VERSION "374"

NS_ :

BS_:

BU_: SensoricSolutionsOMSRace

BO_ 219 BMS_STATUS: 1 ECU
 SG_ acu_state : 0|8@1+ (1,0) [0|255] "" Vector__XXX

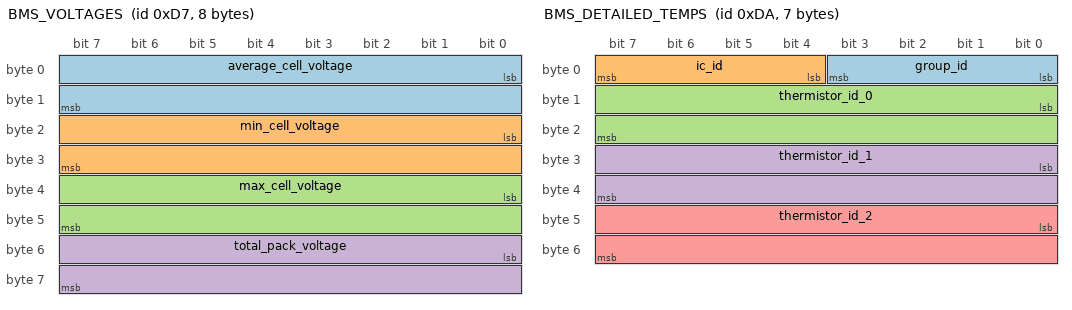
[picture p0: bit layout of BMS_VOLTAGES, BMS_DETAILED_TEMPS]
BO_ 215 BMS_VOLTAGES: 8 ECU
 SG_ average_cell_voltage : 0|16@1+ (0.0001,0) [0.0|6.5535000000000005] "V" Vector__XXX
 SG_ min_cell_voltage : 16|16@1+ (0.0001,0) [0.0|6.5535000000000005] "" Vector__XXX
 SG_ max_cell_voltage : 32|16@1+ (0.0001,0) [0.0|6.5535000000000005] "V" Vector__XXX
 SG_ total_pack_voltage : 48|16@1+ (0.01,0) [0.0|655.35] "" Vector__XXX

BO_ 218 BMS_DETAILED_TEMPS: 7 ECU
 SG_ group_id : 0|4@1+ (1,0) [0|15] "" Vector__XXX
 SG_ ic_id : 4|4@1+ (1,0) [0|15] "" Vector__XXX
 SG_ thermistor_id_0 : 8|16@1- (0.01,0) [-327.68|327.67] "" Vector__XXX
 SG_ thermistor_id_1 : 24|16@1- (0.01,0) [-327.68|327.67] "" Vector__XXX
 SG_ thermistor_id_2 : 40|16@1- (0.01,0) [-327.68|327.67] "" Vector__XXX

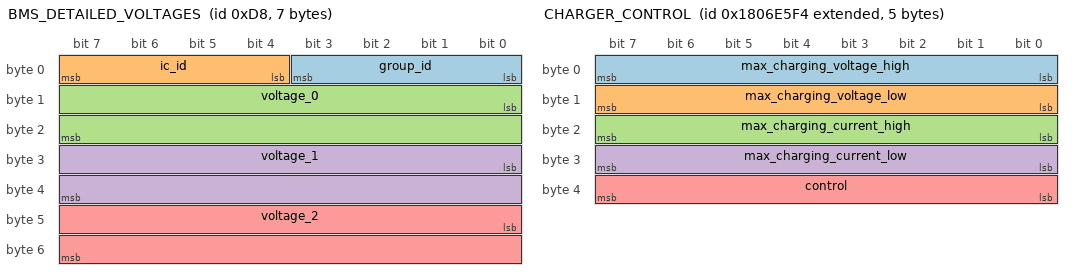
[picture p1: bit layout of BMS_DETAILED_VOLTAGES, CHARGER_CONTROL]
BO_ 216 BMS_DETAILED_VOLTAGES: 7 ECU
 SG_ group_id : 0|4@1+ (1,0) [0|15] "" Vector__XXX
 SG_ ic_id : 4|4@1+ (1,0) [0|15] "" Vector__XXX
 SG_ voltage_0 : 8|16@1+ (0.0001,0) [0.0|6.5535000000000005] "" Vector__XXX
 SG_ voltage_1 : 24|16@1+ (0.0001,0) [0.0|6.5535000000000005] "" Vector__XXX
 SG_ voltage_2 : 40|16@1+ (0.0001,0) [0.0|6.5535000000000005] "" Vector__XXX

BO_ 214 BMS_BOARD_DETAILED_TEMPS: 5 ECU
 SG_ ic_id : 0|4@1+ (1,0) [0|15] "" Vector__XXX
 SG_ temp_0 : 8|16@1- (0.01,0) [-327.68|327.67] "Deg C" Vector__XXX
 SG_ temp_1 : 24|16@1- (0.01,0) [-327.68|327.67] "Deg C" Vector__XXX

BO_ 217 BMS_TEMPS: 6 ECU
 SG_ max_board_temp : 0|16@1- (0.01,0) [-327.68|327.67] "Deg C" Vector__XXX
 SG_ min_cell_temp : 16|16@1- (0.01,0) [-327.68|327.67] "Deg C" Vector__XXX
 SG_ max_cell_temp : 32|16@1- (0.01,0) [-327.68|327.67] "Deg C" Vector__XXX

BO_ 221 CCU_STATUS: 1 ECU
 SG_ charger_enabled : 0|1@1+ (1,0) [0|1] "" Vector__XXX

BO_ 2550588916 CHARGER_CONTROL: 5 ECU
 SG_ max_charging_voltage_high : 0|8@1+ (1,0) [0|255] "" Vector__XXX
 SG_ max_charging_voltage_low : 8|8@1+ (1,0) [0|255] "" Vector__XXX
 SG_ max_charging_current_high : 16|8@1+ (1,0) [0|255] "" Vector__XXX
 SG_ max_charging_current_low : 24|8@1+ (1,0) [0|255] "" Vector__XXX
 SG_ control : 32|8@1+ (1,0) [0|255] "" Vector__XXX

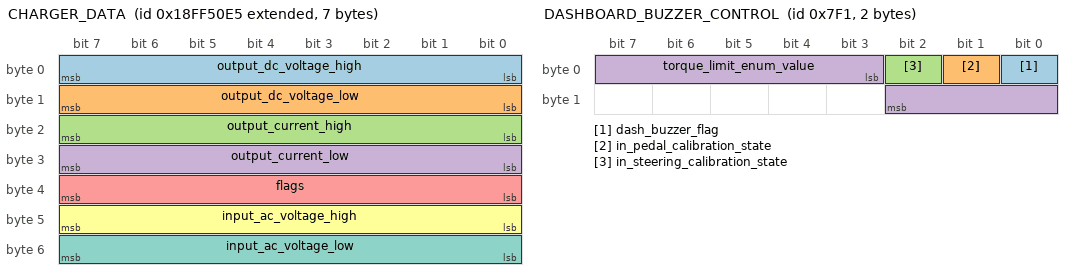
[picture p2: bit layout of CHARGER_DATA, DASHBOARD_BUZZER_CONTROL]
BO_ 2566869221 CHARGER_DATA: 7 ECU
 SG_ output_dc_voltage_high : 0|8@1+ (1,0) [0|255] "" Vector__XXX
 SG_ output_dc_voltage_low : 8|8@1+ (1,0) [0|255] "" Vector__XXX
 SG_ output_current_high : 16|8@1+ (1,0) [0|255] "" Vector__XXX
 SG_ output_current_low : 24|8@1+ (1,0) [0|255] "" Vector__XXX
 SG_ flags : 32|8@1+ (1,0) [0|255] "" Vector__XXX
 SG_ input_ac_voltage_high : 40|8@1+ (1,0) [0|255] "" Vector__XXX
 SG_ input_ac_voltage_low : 48|8@1+ (1,0) [0|255] "" Vector__XXX

BO_ 2033 DASHBOARD_BUZZER_CONTROL: 2 ECU
 SG_ dash_buzzer_flag : 0|1@1+ (1,0) [0|1] "" Vector__XXX
 SG_ in_pedal_calibration_state : 1|1@1+ (1,0) [0|1] "" Vector__XXX
 SG_ in_steering_calibration_state : 2|1@1+ (1,0) [0|1] "" Vector__XXX
 SG_ torque_limit_enum_value : 3|8@1+ (1,0) [0|255] "" Vector__XXX

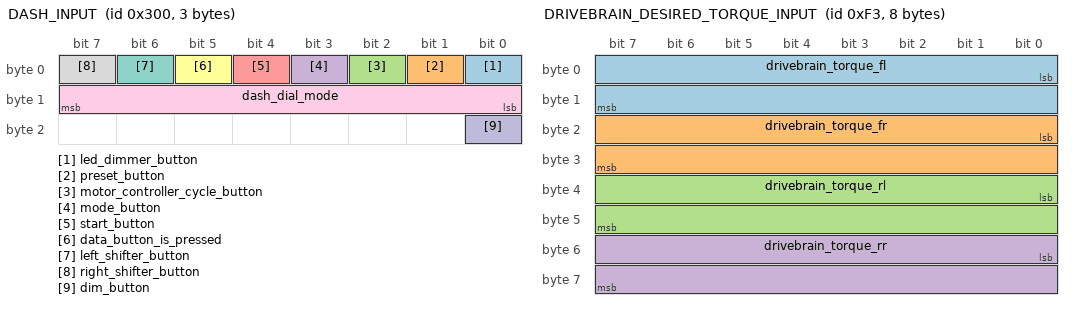
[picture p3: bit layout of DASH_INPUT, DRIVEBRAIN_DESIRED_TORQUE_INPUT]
BO_ 768 DASH_INPUT: 3 ECU
 SG_ led_dimmer_button : 0|1@1+ (1,0) [0|1] "" Vector__XXX
 SG_ preset_button : 1|1@1+ (1,0) [0|1] "" Vector__XXX
 SG_ motor_controller_cycle_button : 2|1@1+ (1,0) [0|1] "" Vector__XXX
 SG_ mode_button : 3|1@1+ (1,0) [0|1] "" Vector__XXX
 SG_ start_button : 4|1@1+ (1,0) [0|1] "" Vector__XXX
 SG_ data_button_is_pressed : 5|1@1+ (1,0) [0|1] "" Vector__XXX
 SG_ left_shifter_button : 6|1@1+ (1,0) [0|1] "" Vector__XXX
 SG_ right_shifter_button : 7|1@1+ (1,0) [0|1] "" Vector__XXX
 SG_ dash_dial_mode : 8|8@1+ (1,0) [0|255] "" Vector__XXX
 SG_ dim_button : 16|1@1+ (1,0) [0|1] "" Vector__XXX

BO_ 243 DRIVEBRAIN_DESIRED_TORQUE_INPUT: 8 ECU
 SG_ drivebrain_torque_fl : 0|16@1- (0.01,0) [-327.68|327.67] "" Vector__XXX
 SG_ drivebrain_torque_fr : 16|16@1- (0.01,0) [-327.68|327.67] "" Vector__XXX
 SG_ drivebrain_torque_rl : 32|16@1- (0.01,0) [-327.68|327.67] "" Vector__XXX
 SG_ drivebrain_torque_rr : 48|16@1- (0.01,0) [-327.68|327.67] "" Vector__XXX

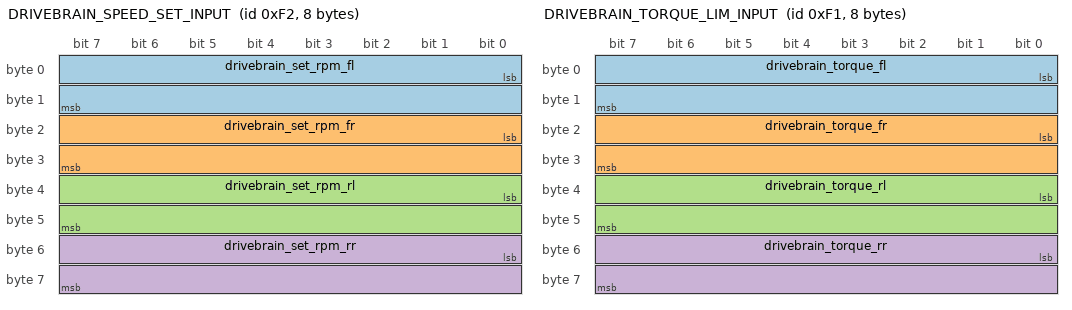
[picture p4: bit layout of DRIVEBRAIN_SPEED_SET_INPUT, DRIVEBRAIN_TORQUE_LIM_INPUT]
BO_ 242 DRIVEBRAIN_SPEED_SET_INPUT: 8 ECU
 SG_ drivebrain_set_rpm_fl : 0|16@1+ (1,0) [0|65535] "" Vector__XXX
 SG_ drivebrain_set_rpm_fr : 16|16@1+ (1,0) [0|65535] "" Vector__XXX
 SG_ drivebrain_set_rpm_rl : 32|16@1+ (1,0) [0|65535] "" Vector__XXX
 SG_ drivebrain_set_rpm_rr : 48|16@1+ (1,0) [0|65535] "" Vector__XXX

BO_ 241 DRIVEBRAIN_TORQUE_LIM_INPUT: 8 ECU
 SG_ drivebrain_torque_fl : 0|16@1- (0.01,0) [-327.68|327.67] "" Vector__XXX
 SG_ drivebrain_torque_fr : 16|16@1- (0.01,0) [-327.68|327.67] "" Vector__XXX
 SG_ drivebrain_torque_rl : 32|16@1- (0.01,0) [-327.68|327.67] "" Vector__XXX
 SG_ drivebrain_torque_rr : 48|16@1- (0.01,0) [-327.68|327.67] "" Vector__XXX

BO_ 244 DRIVEBRAIN_STEERING_INPUT: 2 ECU
 SG_ drivebrain_steering : 0|16@1- (0.01,0) [-327.68|327.67] "degrees" Vector__XXX

BO_ 256 EM_MEASUREMENT: 8 ECU
 SG_ em_current : 7|32@0- (1.52590219e-05,0) [-32768.50001472389|32768.49999946487] "Coulombs" Vector__XXX
 SG_ em_voltage : 39|32@0- (1.52590219e-05,0) [-32768.50001472389|32768.49999946487] "Volts" Vector__XXX

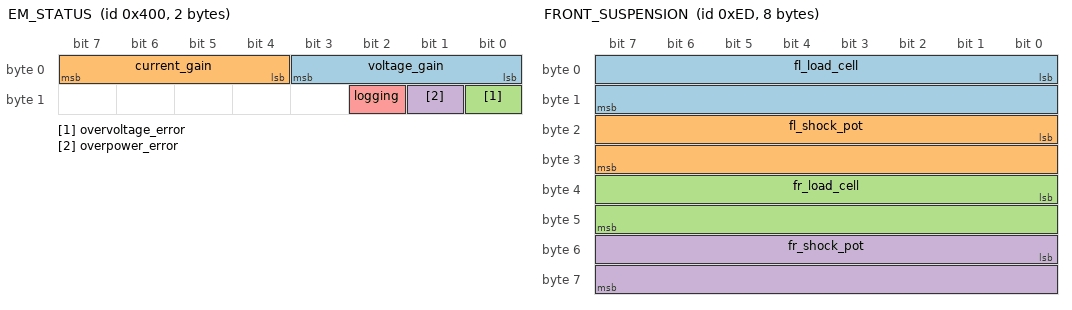
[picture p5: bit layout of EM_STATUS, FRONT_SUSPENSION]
BO_ 1024 EM_STATUS: 2 ECU
 SG_ voltage_gain : 0|4@1+ (1,0) [0|15] "none" Vector__XXX
 SG_ current_gain : 4|4@1+ (1,0) [0|15] "none" Vector__XXX
 SG_ overvoltage_error : 8|1@1+ (1,0) [0|1] "none" Vector__XXX
 SG_ overpower_error : 9|1@1+ (1,0) [0|1] "none" Vector__XXX
 SG_ logging : 10|1@1+ (1,0) [0|1] "none" Vector__XXX

BO_ 237 FRONT_SUSPENSION: 8 ECU
 SG_ fl_load_cell : 0|16@1+ (1,0) [0|65535] "" Vector__XXX
 SG_ fl_shock_pot : 16|16@1+ (0.01,0) [0.0|655.35] "mm" Vector__XXX
 SG_ fr_load_cell : 32|16@1+ (1,0) [0|65535] "" Vector__XXX
 SG_ fr_shock_pot : 48|16@1+ (0.01,0) [0.0|655.35] "" Vector__XXX

BO_ 245 FRONT_THERMISTORS: 8 ECU
 SG_ thermistor_motor_fl : 0|16@1+ (0.005,0) [0.0|327.675] "deg C" Vector__XXX
 SG_ thermistor_motor_fr : 16|16@1+ (0.005,0) [0.0|327.675] "deg C" Vector__XXX

BO_ 153 INV1_CONTROL_INPUT: 6 ECU
 SG_ speed_setpoint_rpm : 0|16@1- (1,0) [-32768|32767] "rpm" Vector__XXX
 SG_ positive_torque_limit : 16|16@1- (0.0097999999999549,0) [-321.1263999985222|321.11659999852225] "Mn" Vector__XXX
 SG_ negative_torque_limit : 32|16@1- (0.0097999999999549,0) [-321.1263999985222|321.11659999852225] "Mn" Vector__XXX

BO_ 261 INV1_CONTROL_PARAMETER: 8 ECU
 SG_ speed_control_kp : 0|16@1+ (1,0) [0|65535] "" Vector__XXX
 SG_ speed_control_ki : 16|16@1+ (1,0) [0|65535] "" Vector__XXX
 SG_ speed_control_kd : 32|16@1+ (1,0) [0|65535] "" Vector__XXX

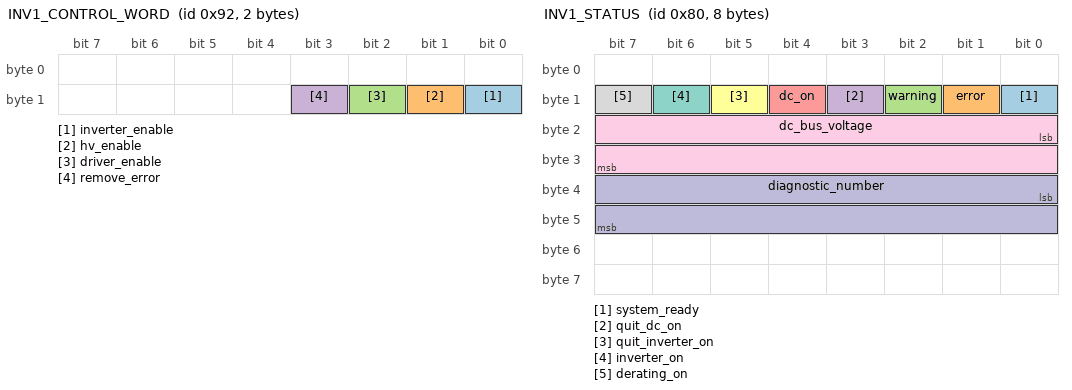
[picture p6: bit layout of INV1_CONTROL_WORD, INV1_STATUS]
BO_ 146 INV1_CONTROL_WORD: 2 ECU
 SG_ inverter_enable : 8|1@1+ (1,0) [0|1] "" Vector__XXX
 SG_ hv_enable : 9|1@1+ (1,0) [0|1] "" Vector__XXX
 SG_ driver_enable : 10|1@1+ (1,0) [0|1] "" Vector__XXX
 SG_ remove_error : 11|1@1+ (1,0) [0|1] "" Vector__XXX

BO_ 130 INV1_DYNAMICS: 8 ECU
 SG_ actual_power_w : 0|32@1+ (1,0) [0|4294967295] "" Vector__XXX
 SG_ actual_torque_nm : 32|16@1- (0.0097999999999549,0) [-321.1263999985222|321.11659999852225] "" Vector__XXX
 SG_ actual_speed_rpm : 48|16@1- (1,0) [-32768|32767] "" Vector__XXX

BO_ 132 INV1_FEEDBACK: 8 ECU
 SG_ speed_control_kp : 0|16@1+ (1,0) [0|65535] "" Vector__XXX
 SG_ speed_control_ki : 16|16@1+ (1,0) [0|65535] "" Vector__XXX
 SG_ speed_control_kd : 32|16@1+ (1,0) [0|65535] "" Vector__XXX

BO_ 131 INV1_POWER: 8 ECU
 SG_ active_power_w : 0|32@1- (1,0) [-2147483648|2147483647] "" Vector__XXX
 SG_ reactive_power_var : 32|32@1- (1,0) [-2147483648|2147483647] "" Vector__XXX

BO_ 128 INV1_STATUS: 8 ECU
 SG_ system_ready : 8|1@1+ (1,0) [0|1] "" Vector__XXX
 SG_ error : 9|1@1+ (1,0) [0|1] "" Vector__XXX
 SG_ warning : 10|1@1+ (1,0) [0|1] "" Vector__XXX
 SG_ quit_dc_on : 11|1@1+ (1,0) [0|1] "" Vector__XXX
 SG_ dc_on : 12|1@1+ (1,0) [0|1] "" Vector__XXX
 SG_ quit_inverter_on : 13|1@1+ (1,0) [0|1] "" Vector__XXX
 SG_ inverter_on : 14|1@1+ (1,0) [0|1] "" Vector__XXX
 SG_ derating_on : 15|1@1+ (1,0) [0|1] "" Vector__XXX
 SG_ dc_bus_voltage : 16|16@1+ (1,0) [0|65535] "V" Vector__XXX
 SG_ diagnostic_number : 32|16@1+ (1,0) [0|65535] "" Vector__XXX

BO_ 129 INV1_TEMPS: 6 ECU
 SG_ motor_temp : 0|16@1- (0.1,0) [-3276.8|3276.7000000000003] "C" Vector__XXX
 SG_ inverter_temp : 16|16@1- (0.1,0) [-3276.8|3276.7000000000003] "C" Vector__XXX
 SG_ igbt_temp : 32|16@1- (0.1,0) [-3276.8|3276.7000000000003] "C" Vector__XXX

BO_ 258 INV2_CONTROL_INPUT: 6 ECU
 SG_ speed_setpoint_rpm : 0|16@1- (1,0) [-32768|32767] "rpm" Vector__XXX
 SG_ positive_torque_limit : 16|16@1- (0.0097999999999549,0) [-321.1263999985222|321.11659999852225] "Mn" Vector__XXX
 SG_ negative_torque_limit : 32|16@1- (0.0097999999999549,0) [-321.1263999985222|321.11659999852225] "Mn" Vector__XXX

BO_ 262 INV2_CONTROL_PARAMETER: 8 ECU
 SG_ speed_control_kp : 0|16@1+ (1,0) [0|65535] "" Vector__XXX
 SG_ speed_control_ki : 16|16@1+ (1,0) [0|65535] "" Vector__XXX
 SG_ speed_control_kd : 32|16@1+ (1,0) [0|65535] "" Vector__XXX

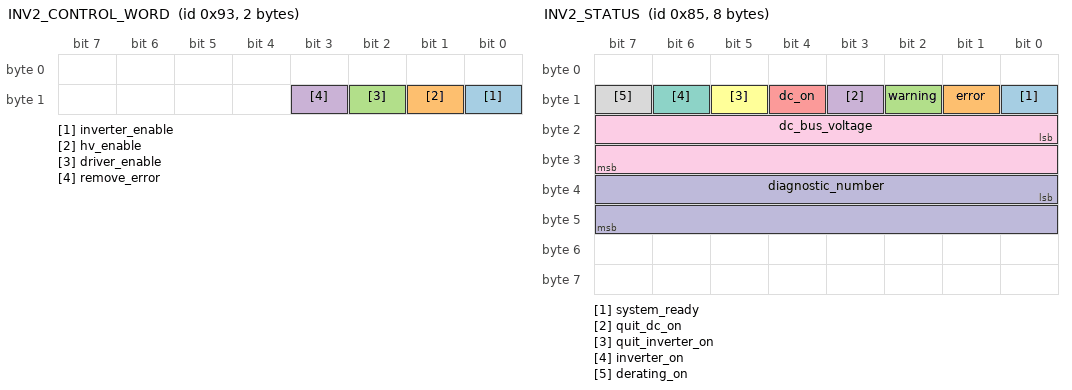
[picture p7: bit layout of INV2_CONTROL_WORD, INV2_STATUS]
BO_ 147 INV2_CONTROL_WORD: 2 ECU
 SG_ inverter_enable : 8|1@1+ (1,0) [0|1] "" Vector__XXX
 SG_ hv_enable : 9|1@1+ (1,0) [0|1] "" Vector__XXX
 SG_ driver_enable : 10|1@1+ (1,0) [0|1] "" Vector__XXX
 SG_ remove_error : 11|1@1+ (1,0) [0|1] "" Vector__XXX

BO_ 135 INV2_DYNAMICS: 8 ECU
 SG_ actual_power_w : 0|32@1+ (1,0) [0|4294967295] "" Vector__XXX
 SG_ actual_torque_nm : 32|16@1- (0.0097999999999549,0) [-321.1263999985222|321.11659999852225] "" Vector__XXX
 SG_ actual_speed_rpm : 48|16@1- (1,0) [-32768|32767] "" Vector__XXX

BO_ 137 INV2_FEEDBACK: 8 ECU
 SG_ speed_control_kp : 0|16@1+ (1,0) [0|65535] "" Vector__XXX
 SG_ speed_control_ki : 16|16@1+ (1,0) [0|65535] "" Vector__XXX
 SG_ speed_control_kd : 32|16@1+ (1,0) [0|65535] "" Vector__XXX

BO_ 136 INV2_POWER: 8 ECU
 SG_ active_power_w : 0|32@1- (1,0) [-2147483648|2147483647] "" Vector__XXX
 SG_ reactive_power_var : 32|32@1- (1,0) [-2147483648|2147483647] "" Vector__XXX

BO_ 133 INV2_STATUS: 8 ECU
 SG_ system_ready : 8|1@1+ (1,0) [0|1] "" Vector__XXX
 SG_ error : 9|1@1+ (1,0) [0|1] "" Vector__XXX
 SG_ warning : 10|1@1+ (1,0) [0|1] "" Vector__XXX
 SG_ quit_dc_on : 11|1@1+ (1,0) [0|1] "" Vector__XXX
 SG_ dc_on : 12|1@1+ (1,0) [0|1] "" Vector__XXX
 SG_ quit_inverter_on : 13|1@1+ (1,0) [0|1] "" Vector__XXX
 SG_ inverter_on : 14|1@1+ (1,0) [0|1] "" Vector__XXX
 SG_ derating_on : 15|1@1+ (1,0) [0|1] "" Vector__XXX
 SG_ dc_bus_voltage : 16|16@1+ (1,0) [0|65535] "V" Vector__XXX
 SG_ diagnostic_number : 32|16@1+ (1,0) [0|65535] "" Vector__XXX

BO_ 134 INV2_TEMPS: 6 ECU
 SG_ motor_temp : 0|16@1- (0.1,0) [-3276.8|3276.7000000000003] "C" Vector__XXX
 SG_ inverter_temp : 16|16@1- (0.1,0) [-3276.8|3276.7000000000003] "C" Vector__XXX
 SG_ igbt_temp : 32|16@1- (0.1,0) [-3276.8|3276.7000000000003] "C" Vector__XXX

BO_ 151 INV3_CONTROL_INPUT: 6 ECU
 SG_ speed_setpoint_rpm : 0|16@1- (1,0) [-32768|32767] "rpm" Vector__XXX
 SG_ positive_torque_limit : 16|16@1- (0.0097999999999549,0) [-321.1263999985222|321.11659999852225] "Mn" Vector__XXX
 SG_ negative_torque_limit : 32|16@1- (0.0097999999999549,0) [-321.1263999985222|321.11659999852225] "Mn" Vector__XXX

BO_ 259 INV3_CONTROL_PARAMETER: 8 ECU
 SG_ speed_control_kp : 0|16@1+ (1,0) [0|65535] "" Vector__XXX
 SG_ speed_control_ki : 16|16@1+ (1,0) [0|65535] "" Vector__XXX
 SG_ speed_control_kd : 32|16@1+ (1,0) [0|65535] "" Vector__XXX

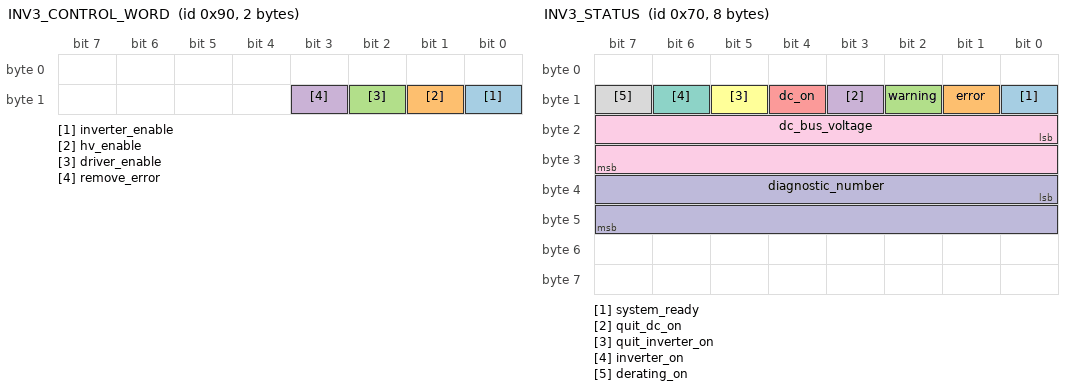
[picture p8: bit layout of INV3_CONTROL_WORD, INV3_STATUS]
BO_ 144 INV3_CONTROL_WORD: 2 ECU
 SG_ inverter_enable : 8|1@1+ (1,0) [0|1] "" Vector__XXX
 SG_ hv_enable : 9|1@1+ (1,0) [0|1] "" Vector__XXX
 SG_ driver_enable : 10|1@1+ (1,0) [0|1] "" Vector__XXX
 SG_ remove_error : 11|1@1+ (1,0) [0|1] "" Vector__XXX

BO_ 114 INV3_DYNAMICS: 8 ECU
 SG_ actual_power_w : 0|32@1+ (1,0) [0|4294967295] "" Vector__XXX
 SG_ actual_torque_nm : 32|16@1- (0.0097999999999549,0) [-321.1263999985222|321.11659999852225] "" Vector__XXX
 SG_ actual_speed_rpm : 48|16@1- (1,0) [-32768|32767] "" Vector__XXX

BO_ 116 INV3_FEEDBACK: 8 ECU
 SG_ speed_control_kp : 0|16@1+ (1,0) [0|65535] "" Vector__XXX
 SG_ speed_control_ki : 16|16@1+ (1,0) [0|65535] "" Vector__XXX
 SG_ speed_control_kd : 32|16@1+ (1,0) [0|65535] "" Vector__XXX

BO_ 115 INV3_POWER: 8 ECU
 SG_ active_power_w : 0|32@1- (1,0) [-2147483648|2147483647] "" Vector__XXX
 SG_ reactive_power_var : 32|32@1- (1,0) [-2147483648|2147483647] "" Vector__XXX

BO_ 112 INV3_STATUS: 8 ECU
 SG_ system_ready : 8|1@1+ (1,0) [0|1] "" Vector__XXX
 SG_ error : 9|1@1+ (1,0) [0|1] "" Vector__XXX
 SG_ warning : 10|1@1+ (1,0) [0|1] "" Vector__XXX
 SG_ quit_dc_on : 11|1@1+ (1,0) [0|1] "" Vector__XXX
 SG_ dc_on : 12|1@1+ (1,0) [0|1] "" Vector__XXX
 SG_ quit_inverter_on : 13|1@1+ (1,0) [0|1] "" Vector__XXX
 SG_ inverter_on : 14|1@1+ (1,0) [0|1] "" Vector__XXX
 SG_ derating_on : 15|1@1+ (1,0) [0|1] "" Vector__XXX
 SG_ dc_bus_voltage : 16|16@1+ (1,0) [0|65535] "V" Vector__XXX
 SG_ diagnostic_number : 32|16@1+ (1,0) [0|65535] "" Vector__XXX

BO_ 113 INV3_TEMPS: 6 ECU
 SG_ motor_temp : 0|16@1- (0.1,0) [-3276.8|3276.7000000000003] "C" Vector__XXX
 SG_ inverter_temp : 16|16@1- (0.1,0) [-3276.8|3276.7000000000003] "C" Vector__XXX
 SG_ igbt_temp : 32|16@1- (0.1,0) [-3276.8|3276.7000000000003] "C" Vector__XXX

BO_ 152 INV4_CONTROL_INPUT: 6 ECU
 SG_ speed_setpoint_rpm : 0|16@1- (1,0) [-32768|32767] "rpm" Vector__XXX
 SG_ positive_torque_limit : 16|16@1- (0.0097999999999549,0) [-321.1263999985222|321.11659999852225] "Mn" Vector__XXX
 SG_ negative_torque_limit : 32|16@1- (0.0097999999999549,0) [-321.1263999985222|321.11659999852225] "Mn" Vector__XXX

BO_ 260 INV4_CONTROL_PARAMETER: 8 ECU
 SG_ speed_control_kp : 0|16@1+ (1,0) [0|65535] "" Vector__XXX
 SG_ speed_control_ki : 16|16@1+ (1,0) [0|65535] "" Vector__XXX
 SG_ speed_control_kd : 32|16@1+ (1,0) [0|65535] "" Vector__XXX

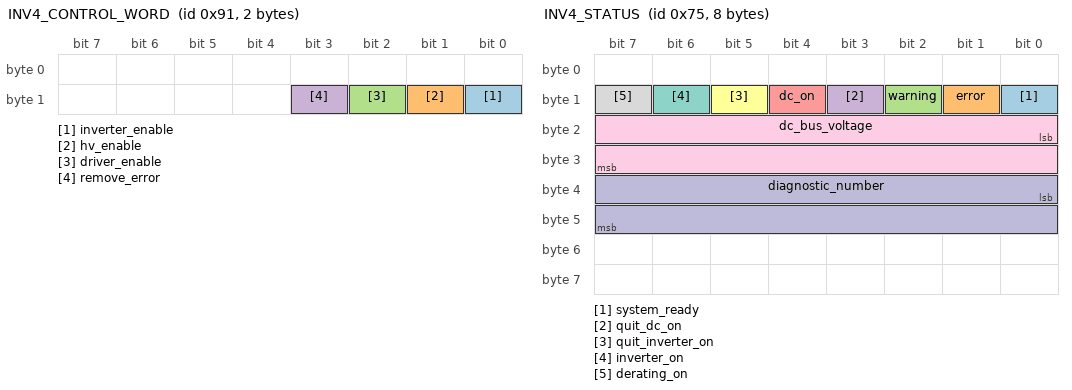
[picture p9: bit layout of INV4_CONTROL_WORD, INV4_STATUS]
BO_ 145 INV4_CONTROL_WORD: 2 ECU
 SG_ inverter_enable : 8|1@1+ (1,0) [0|1] "" Vector__XXX
 SG_ hv_enable : 9|1@1+ (1,0) [0|1] "" Vector__XXX
 SG_ driver_enable : 10|1@1+ (1,0) [0|1] "" Vector__XXX
 SG_ remove_error : 11|1@1+ (1,0) [0|1] "" Vector__XXX

BO_ 119 INV4_DYNAMICS: 8 ECU
 SG_ actual_power_w : 0|32@1+ (1,0) [0|4294967295] "" Vector__XXX
 SG_ actual_torque_nm : 32|16@1- (0.0097999999999549,0) [-321.1263999985222|321.11659999852225] "" Vector__XXX
 SG_ actual_speed_rpm : 48|16@1- (1,0) [-32768|32767] "" Vector__XXX

BO_ 121 INV4_FEEDBACK: 8 ECU
 SG_ speed_control_kp : 0|16@1+ (1,0) [0|65535] "" Vector__XXX
 SG_ speed_control_ki : 16|16@1+ (1,0) [0|65535] "" Vector__XXX
 SG_ speed_control_kd : 32|16@1+ (1,0) [0|65535] "" Vector__XXX

BO_ 120 INV4_POWER: 8 ECU
 SG_ active_power_w : 0|32@1- (1,0) [-2147483648|2147483647] "" Vector__XXX
 SG_ reactive_power_var : 32|32@1- (1,0) [-2147483648|2147483647] "" Vector__XXX

BO_ 117 INV4_STATUS: 8 ECU
 SG_ system_ready : 8|1@1+ (1,0) [0|1] "" Vector__XXX
 SG_ error : 9|1@1+ (1,0) [0|1] "" Vector__XXX
 SG_ warning : 10|1@1+ (1,0) [0|1] "" Vector__XXX
 SG_ quit_dc_on : 11|1@1+ (1,0) [0|1] "" Vector__XXX
 SG_ dc_on : 12|1@1+ (1,0) [0|1] "" Vector__XXX
 SG_ quit_inverter_on : 13|1@1+ (1,0) [0|1] "" Vector__XXX
 SG_ inverter_on : 14|1@1+ (1,0) [0|1] "" Vector__XXX
 SG_ derating_on : 15|1@1+ (1,0) [0|1] "" Vector__XXX
 SG_ dc_bus_voltage : 16|16@1+ (1,0) [0|65535] "V" Vector__XXX
 SG_ diagnostic_number : 32|16@1+ (1,0) [0|65535] "" Vector__XXX

BO_ 118 INV4_TEMPS: 6 ECU
 SG_ motor_temp : 0|16@1- (0.1,0) [-3276.8|3276.7000000000003] "C" Vector__XXX
 SG_ inverter_temp : 16|16@1- (0.1,0) [-3276.8|3276.7000000000003] "C" Vector__XXX
 SG_ igbt_temp : 32|16@1- (0.1,0) [-3276.8|3276.7000000000003] "C" Vector__XXX

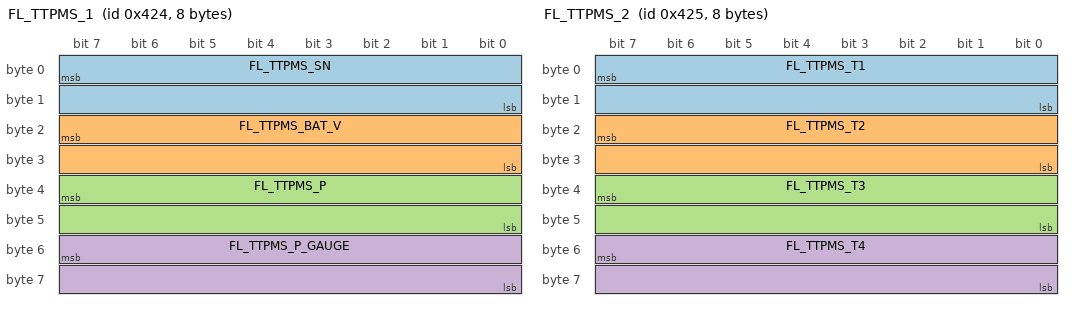
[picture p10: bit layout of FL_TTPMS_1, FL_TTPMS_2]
BO_ 1060 FL_TTPMS_1: 8 ECU
 SG_ FL_TTPMS_SN : 7|16@0+ (1,0) [0|65535] "" Vector__XXX
 SG_ FL_TTPMS_BAT_V : 23|16@0+ (1,0) [0|65535] "mV" Vector__XXX
 SG_ FL_TTPMS_P : 39|16@0- (0.1,3000) [-276.8000000000002|6276.700000000001] "mbar" Vector__XXX
 SG_ FL_TTPMS_P_GAUGE : 55|16@0+ (1,0) [0|65535] "mbar" Vector__XXX

BO_ 1061 FL_TTPMS_2: 8 ECU
 SG_ FL_TTPMS_T1 : 7|16@0+ (0.1,-100) [-100.0|6453.5] "°C" Vector__XXX
 SG_ FL_TTPMS_T2 : 23|16@0+ (0.1,-100) [-100.0|6453.5] "°C" Vector__XXX
 SG_ FL_TTPMS_T3 : 39|16@0+ (0.1,-100) [-100.0|6453.5] "°C" Vector__XXX
 SG_ FL_TTPMS_T4 : 55|16@0+ (0.1,-100) [-100.0|6453.5] "°C" Vector__XXX

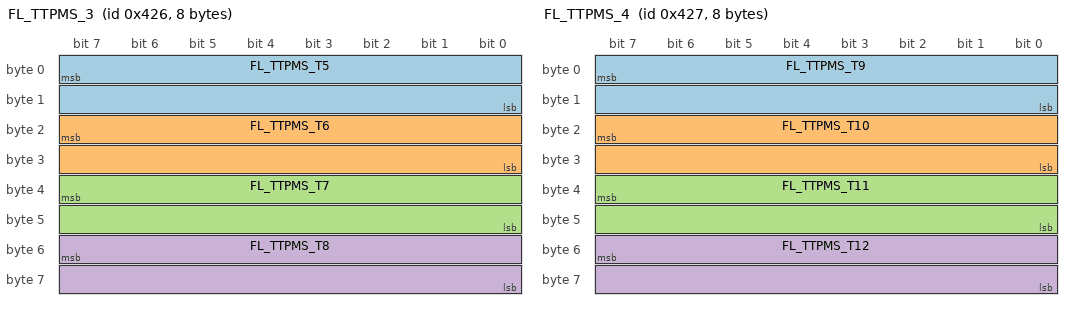
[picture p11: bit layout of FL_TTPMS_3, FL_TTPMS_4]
BO_ 1062 FL_TTPMS_3: 8 ECU
 SG_ FL_TTPMS_T5 : 7|16@0+ (0.1,-100) [-100.0|6453.5] "°C" Vector__XXX
 SG_ FL_TTPMS_T6 : 23|16@0+ (0.1,-100) [-100.0|6453.5] "°C" Vector__XXX
 SG_ FL_TTPMS_T7 : 39|16@0+ (0.1,-100) [-100.0|6453.5] "°C" Vector__XXX
 SG_ FL_TTPMS_T8 : 55|16@0+ (0.1,-100) [-100.0|6453.5] "°C" Vector__XXX

BO_ 1063 FL_TTPMS_4: 8 ECU
 SG_ FL_TTPMS_T9 : 7|16@0+ (0.1,-100) [-100.0|6453.5] "°C" Vector__XXX
 SG_ FL_TTPMS_T10 : 23|16@0+ (0.1,-100) [-100.0|6453.5] "°C" Vector__XXX
 SG_ FL_TTPMS_T11 : 39|16@0+ (0.1,-100) [-100.0|6453.5] "°C" Vector__XXX
 SG_ FL_TTPMS_T12 : 55|16@0+ (0.1,-100) [-100.0|6453.5] "°C" Vector__XXX

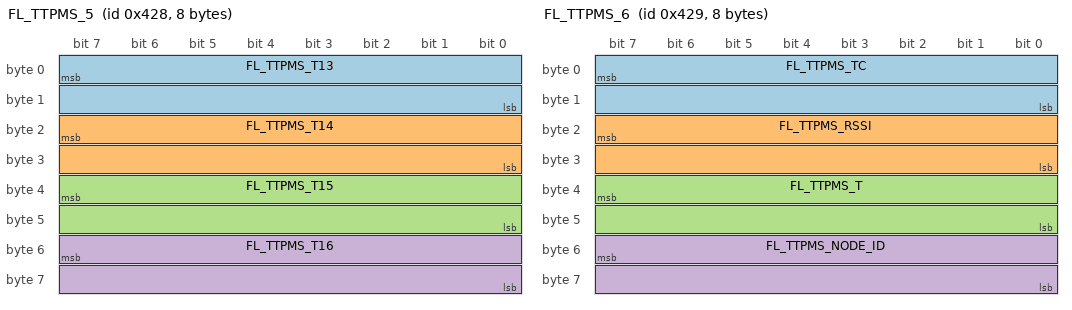
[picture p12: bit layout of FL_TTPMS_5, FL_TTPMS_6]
BO_ 1064 FL_TTPMS_5: 8 ECU
 SG_ FL_TTPMS_T13 : 7|16@0+ (0.1,-100) [-100.0|6453.5] "°C" Vector__XXX
 SG_ FL_TTPMS_T14 : 23|16@0+ (0.1,-100) [-100.0|6453.5] "°C" Vector__XXX
 SG_ FL_TTPMS_T15 : 39|16@0+ (0.1,-100) [-100.0|6453.5] "°C" Vector__XXX
 SG_ FL_TTPMS_T16 : 55|16@0+ (0.1,-100) [-100.0|6453.5] "°C" Vector__XXX

BO_ 1065 FL_TTPMS_6: 8 ECU
 SG_ FL_TTPMS_TC : 7|16@0+ (1,0) [0|65535] "" Vector__XXX
 SG_ FL_TTPMS_RSSI : 23|16@0- (1,0) [-32768|32767] "dBm" Vector__XXX
 SG_ FL_TTPMS_T : 39|16@0+ (0.1,-100) [-100.0|6453.5] "°C" Vector__XXX
 SG_ FL_TTPMS_NODE_ID : 55|16@0+ (1,0) [0|65535] "" Vector__XXX

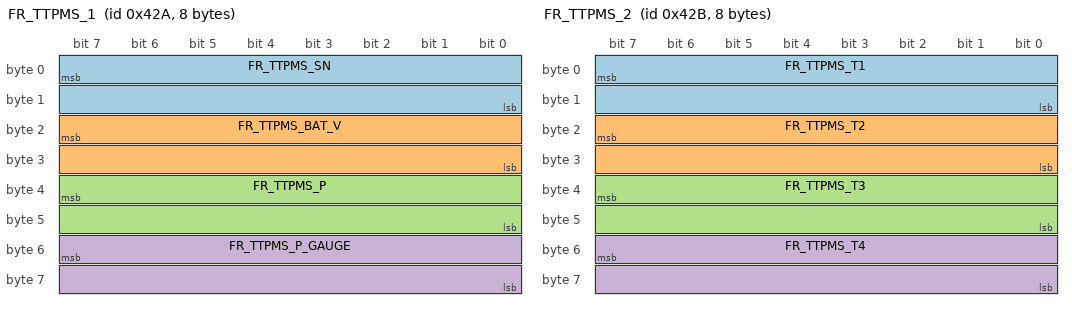
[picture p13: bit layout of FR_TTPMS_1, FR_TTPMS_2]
BO_ 1066 FR_TTPMS_1: 8 ECU
 SG_ FR_TTPMS_SN : 7|16@0+ (1,0) [0|65535] "" Vector__XXX
 SG_ FR_TTPMS_BAT_V : 23|16@0+ (1,0) [0|65535] "mV" Vector__XXX
 SG_ FR_TTPMS_P : 39|16@0- (0.1,3000) [-276.8000000000002|6276.700000000001] "mbar" Vector__XXX
 SG_ FR_TTPMS_P_GAUGE : 55|16@0+ (1,0) [0|65535] "mbar" Vector__XXX

BO_ 1067 FR_TTPMS_2: 8 ECU
 SG_ FR_TTPMS_T1 : 7|16@0+ (0.1,-100) [-100.0|6453.5] "°C" Vector__XXX
 SG_ FR_TTPMS_T2 : 23|16@0+ (0.1,-100) [-100.0|6453.5] "°C" Vector__XXX
 SG_ FR_TTPMS_T3 : 39|16@0+ (0.1,-100) [-100.0|6453.5] "°C" Vector__XXX
 SG_ FR_TTPMS_T4 : 55|16@0+ (0.1,-100) [-100.0|6453.5] "°C" Vector__XXX

BO_ 1068 FR_TTPMS_3: 8 ECU
 SG_ FR_TTPMS_T5 : 7|16@0+ (0.1,-100) [-100.0|6453.5] "°C" Vector__XXX
 SG_ FR_TTPMS_T6 : 23|16@0+ (0.1,-100) [-100.0|6453.5] "°C" Vector__XXX
 SG_ FR_TTPMS_T7 : 39|16@0+ (0.1,-100) [-100.0|6453.5] "°C" Vector__XXX
 SG_ FR_TTPMS_T8 : 55|16@0+ (0.1,-100) [-100.0|6453.5] "°C" Vector__XXX

BO_ 1069 FR_TTPMS_4: 8 ECU
 SG_ FR_TTPMS_T9 : 7|16@0+ (0.1,-100) [-100.0|6453.5] "°C" Vector__XXX
 SG_ FR_TTPMS_T10 : 23|16@0+ (0.1,-100) [-100.0|6453.5] "°C" Vector__XXX
 SG_ FR_TTPMS_T11 : 39|16@0+ (0.1,-100) [-100.0|6453.5] "°C" Vector__XXX
 SG_ FR_TTPMS_T12 : 55|16@0+ (0.1,-100) [-100.0|6453.5] "°C" Vector__XXX

BO_ 1070 FR_TTPMS_5: 8 ECU
 SG_ FR_TTPMS_T13 : 7|16@0+ (0.1,-100) [-100.0|6453.5] "°C" Vector__XXX
 SG_ FR_TTPMS_T14 : 23|16@0+ (0.1,-100) [-100.0|6453.5] "°C" Vector__XXX
 SG_ FR_TTPMS_T15 : 39|16@0+ (0.1,-100) [-100.0|6453.5] "°C" Vector__XXX
 SG_ FR_TTPMS_T16 : 55|16@0+ (0.1,-100) [-100.0|6453.5] "°C" Vector__XXX

BO_ 1071 FR_TTPMS_6: 8 ECU
 SG_ FR_TTPMS_TC : 7|16@0+ (1,0) [0|65535] "" Vector__XXX
 SG_ FR_TTPMS_RSSI : 23|16@0- (1,0) [-32768|32767] "dBm" Vector__XXX
 SG_ FR_TTPMS_T : 39|16@0+ (0.1,-100) [-100.0|6453.5] "°C" Vector__XXX
 SG_ FR_TTPMS_NODE_ID : 55|16@0+ (1,0) [0|65535] "" Vector__XXX

BO_ 1072 RL_TTPMS_1: 8 ECU
 SG_ RL_TTPMS_SN : 7|16@0+ (1,0) [0|65535] "" Vector__XXX
 SG_ RL_TTPMS_BAT_V : 23|16@0+ (1,0) [0|65535] "mV" Vector__XXX
 SG_ RL_TTPMS_P : 39|16@0- (0.1,3000) [-276.8000000000002|6276.700000000001] "mbar" Vector__XXX
 SG_ RL_TTPMS_P_GAUGE : 55|16@0+ (1,0) [0|65535] "mbar" Vector__XXX

BO_ 1073 RL_TTPMS_2: 8 ECU
 SG_ RL_TTPMS_T1 : 7|16@0+ (0.1,-100) [-100.0|6453.5] "°C" Vector__XXX
 SG_ RL_TTPMS_T2 : 23|16@0+ (0.1,-100) [-100.0|6453.5] "°C" Vector__XXX
 SG_ RL_TTPMS_T3 : 39|16@0+ (0.1,-100) [-100.0|6453.5] "°C" Vector__XXX
 SG_ RL_TTPMS_T4 : 55|16@0+ (0.1,-100) [-100.0|6453.5] "°C" Vector__XXX

BO_ 1074 RL_TTPMS_3: 8 ECU
 SG_ RL_TTPMS_T5 : 7|16@0+ (0.1,-100) [-100.0|6453.5] "°C" Vector__XXX
 SG_ RL_TTPMS_T6 : 23|16@0+ (0.1,-100) [-100.0|6453.5] "°C" Vector__XXX
 SG_ RL_TTPMS_T7 : 39|16@0+ (0.1,-100) [-100.0|6453.5] "°C" Vector__XXX
 SG_ RL_TTPMS_T8 : 55|16@0+ (0.1,-100) [-100.0|6453.5] "°C" Vector__XXX

BO_ 1075 RL_TTPMS_4: 8 ECU
 SG_ RL_TTPMS_T9 : 7|16@0+ (0.1,-100) [-100.0|6453.5] "°C" Vector__XXX
 SG_ RL_TTPMS_T10 : 23|16@0+ (0.1,-100) [-100.0|6453.5] "°C" Vector__XXX
 SG_ RL_TTPMS_T11 : 39|16@0+ (0.1,-100) [-100.0|6453.5] "°C" Vector__XXX
 SG_ RL_TTPMS_T12 : 55|16@0+ (0.1,-100) [-100.0|6453.5] "°C" Vector__XXX

BO_ 1076 RL_TTPMS_5: 8 ECU
 SG_ RL_TTPMS_T13 : 7|16@0+ (0.1,-100) [-100.0|6453.5] "°C" Vector__XXX
 SG_ RL_TTPMS_T14 : 23|16@0+ (0.1,-100) [-100.0|6453.5] "°C" Vector__XXX
 SG_ RL_TTPMS_T15 : 39|16@0+ (0.1,-100) [-100.0|6453.5] "°C" Vector__XXX
 SG_ RL_TTPMS_T16 : 55|16@0+ (0.1,-100) [-100.0|6453.5] "°C" Vector__XXX

BO_ 1077 RL_TTPMS_6: 8 ECU
 SG_ RL_TTPMS_TC : 7|16@0+ (1,0) [0|65535] "" Vector__XXX
 SG_ RL_TTPMS_RSSI : 23|16@0- (1,0) [-32768|32767] "dBm" Vector__XXX
 SG_ RL_TTPMS_T : 39|16@0+ (0.1,-100) [-100.0|6453.5] "°C" Vector__XXX
 SG_ RL_TTPMS_NODE_ID : 55|16@0+ (1,0) [0|65535] "" Vector__XXX

BO_ 1078 RR_TTPMS_1: 8 ECU
 SG_ RR_TTPMS_SN : 7|16@0+ (1,0) [0|65535] "" Vector__XXX
 SG_ RR_TTPMS_BAT_V : 23|16@0+ (1,0) [0|65535] "mV" Vector__XXX
 SG_ RR_TTPMS_P : 39|16@0- (0.1,3000) [-276.8000000000002|6276.700000000001] "mbar" Vector__XXX
 SG_ RR_TTPMS_P_GAUGE : 55|16@0+ (1,0) [0|65535] "mbar" Vector__XXX

BO_ 1079 RR_TTPMS_2: 8 ECU
 SG_ RR_TTPMS_T1 : 7|16@0+ (0.1,-100) [-100.0|6453.5] "°C" Vector__XXX
 SG_ RR_TTPMS_T2 : 23|16@0+ (0.1,-100) [-100.0|6453.5] "°C" Vector__XXX
 SG_ RR_TTPMS_T3 : 39|16@0+ (0.1,-100) [-100.0|6453.5] "°C" Vector__XXX
 SG_ RR_TTPMS_T4 : 55|16@0+ (0.1,-100) [-100.0|6453.5] "°C" Vector__XXX

BO_ 1080 RR_TTPMS_3: 8 ECU
 SG_ RR_TTPMS_T5 : 7|16@0+ (0.1,-100) [-100.0|6453.5] "°C" Vector__XXX
 SG_ RR_TTPMS_T6 : 23|16@0+ (0.1,-100) [-100.0|6453.5] "°C" Vector__XXX
 SG_ RR_TTPMS_T7 : 39|16@0+ (0.1,-100) [-100.0|6453.5] "°C" Vector__XXX
 SG_ RR_TTPMS_T8 : 55|16@0+ (0.1,-100) [-100.0|6453.5] "°C" Vector__XXX

BO_ 1081 RR_TTPMS_4: 8 ECU
 SG_ RR_TTPMS_T9 : 7|16@0+ (0.1,-100) [-100.0|6453.5] "°C" Vector__XXX
 SG_ RR_TTPMS_T10 : 23|16@0+ (0.1,-100) [-100.0|6453.5] "°C" Vector__XXX
 SG_ RR_TTPMS_T11 : 39|16@0+ (0.1,-100) [-100.0|6453.5] "°C" Vector__XXX
 SG_ RR_TTPMS_T12 : 55|16@0+ (0.1,-100) [-100.0|6453.5] "°C" Vector__XXX

BO_ 1082 RR_TTPMS_5: 8 ECU
 SG_ RR_TTPMS_T13 : 7|16@0+ (0.1,-100) [-100.0|6453.5] "°C" Vector__XXX
 SG_ RR_TTPMS_T14 : 23|16@0+ (0.1,-100) [-100.0|6453.5] "°C" Vector__XXX
 SG_ RR_TTPMS_T15 : 39|16@0+ (0.1,-100) [-100.0|6453.5] "°C" Vector__XXX
 SG_ RR_TTPMS_T16 : 55|16@0+ (0.1,-100) [-100.0|6453.5] "°C" Vector__XXX

BO_ 1083 RR_TTPMS_6: 8 ECU
 SG_ RR_TTPMS_TC : 7|16@0+ (1,0) [0|65535] "" Vector__XXX
 SG_ RR_TTPMS_RSSI : 23|16@0- (1,0) [-32768|32767] "dBm" Vector__XXX
 SG_ RR_TTPMS_T : 39|16@0+ (0.1,-100) [-100.0|6453.5] "°C" Vector__XXX
 SG_ RR_TTPMS_NODE_ID : 55|16@0+ (1,0) [0|65535] "" Vector__XXX

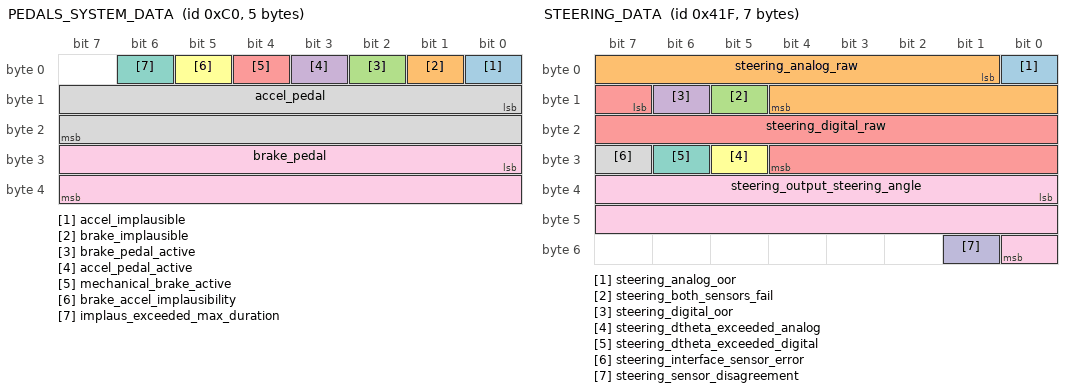
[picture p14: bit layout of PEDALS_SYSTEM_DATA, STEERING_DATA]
BO_ 192 PEDALS_SYSTEM_DATA: 5 ECU
 SG_ accel_implausible : 0|1@1+ (1,0) [0|1] "" Vector__XXX
 SG_ brake_implausible : 1|1@1+ (1,0) [0|1] "" Vector__XXX
 SG_ brake_pedal_active : 2|1@1+ (1,0) [0|1] "" Vector__XXX
 SG_ accel_pedal_active : 3|1@1+ (1,0) [0|1] "" Vector__XXX
 SG_ mechanical_brake_active : 4|1@1+ (1,0) [0|1] "" Vector__XXX
 SG_ brake_accel_implausibility : 5|1@1+ (1,0) [0|1] "" Vector__XXX
 SG_ implaus_exceeded_max_duration : 6|1@1+ (1,0) [0|1] "" Vector__XXX
 SG_ accel_pedal : 8|16@1+ (1.5259e-05,0) [0.0|0.9999985650000001] "" Vector__XXX
 SG_ brake_pedal : 24|16@1+ (1.5259e-05,0) [0.0|0.9999985650000001] "" Vector__XXX

BO_ 228 REAR_SUSPENSION: 8 ECU
 SG_ rl_load_cell : 0|16@1+ (1,0) [0|65535] "" Vector__XXX
 SG_ rr_load_cell : 16|16@1+ (1,0) [0|65535] "" Vector__XXX
 SG_ rl_shock_pot : 32|16@1+ (0.01,0) [0.0|655.35] "" Vector__XXX
 SG_ rr_shock_pot : 48|16@1+ (0.01,0) [0.0|655.35] "" Vector__XXX

BO_ 238 REAR_THERMISTORS_DATA: 8 ECU
 SG_ thermistor_0_deg_C : 0|16@1+ (0.005,0) [0.0|327.675] "deg C" Vector__XXX
 SG_ thermistor_1_deg_C : 16|16@1+ (0.005,0) [0.0|327.675] "deg C" Vector__XXX
 SG_ thermistor_2_deg_C : 32|16@1+ (0.005,0) [0.0|327.675] "deg C" Vector__XXX
 SG_ thermistor_3_deg_C : 48|16@1+ (0.005,0) [0.0|327.675] "deg C" Vector__XXX

BO_ 1054 STATE_OF_CHARGE: 8 ECU
 SG_ SoC : 0|16@1+ (0.01,0) [0.0|655.35] "percent" Vector__XXX
 SG_ min_cell_voltage_est : 16|16@1+ (0.0001,0) [0.0|6.5535000000000005] "volts" Vector__XXX
 SG_ charge_coulombs : 32|32@1+ (0.0001,0) [0.0|429496.7295] "Coulombs" Vector__XXX

BO_ 1055 STEERING_DATA: 7 ECU
 SG_ steering_analog_oor : 0|1@1+ (1,0) [0|1] "" Vector__XXX
 SG_ steering_analog_raw : 1|12@1+ (1,0) [0|4095] "" Vector__XXX
 SG_ steering_both_sensors_fail : 13|1@1+ (1,0) [0|1] "" Vector__XXX
 SG_ steering_digital_oor : 14|1@1+ (1,0) [0|1] "" Vector__XXX
 SG_ steering_digital_raw : 15|14@1+ (1,0) [0|16383] "" Vector__XXX
 SG_ steering_dtheta_exceeded_analog : 29|1@1+ (1,0) [0|1] "" Vector__XXX
 SG_ steering_dtheta_exceeded_digital : 30|1@1+ (1,0) [0|1] "" Vector__XXX
 SG_ steering_interface_sensor_error : 31|1@1+ (1,0) [0|1] "" Vector__XXX
 SG_ steering_output_steering_angle : 32|17@1+ (0.01,-360) [-360.0|950.71] "degrees" Vector__XXX
 SG_ steering_sensor_disagreement : 49|1@1+ (1,0) [0|1] "" Vector__XXX

BO_ 2047 VEHM_ALPHA: 8 ECU
 SG_ vehm_alpha_deg_fl : 0|16@1- (0.001,0) [-32.768|32.767] "deg" Vector__XXX
 SG_ vehm_alpha_deg_fr : 16|16@1- (0.001,0) [-32.768|32.767] "deg" Vector__XXX
 SG_ vehm_alpha_deg_rl : 32|16@1- (0.001,0) [-32.768|32.767] "deg" Vector__XXX
 SG_ vehm_alpha_deg_rr : 48|16@1- (0.001,0) [-32.768|32.767] "deg" Vector__XXX

BO_ 2031 VEHM_BETA: 8 ECU
 SG_ vehm_beta_deg : 0|16@1- (0.001,0) [-32.768|32.767] "deg" Vector__XXX

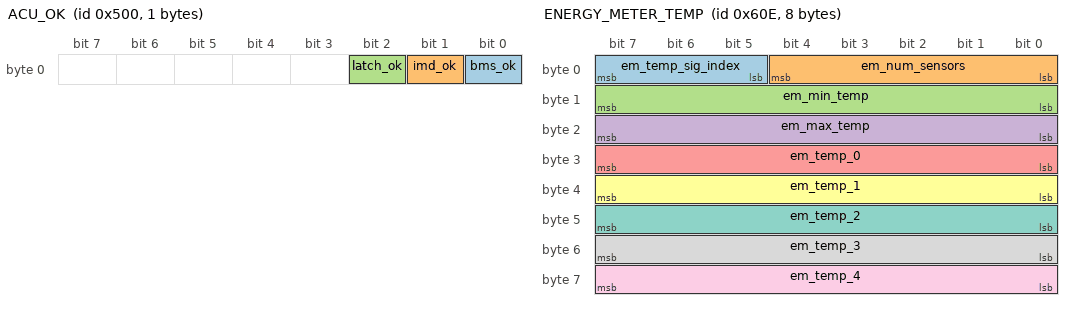
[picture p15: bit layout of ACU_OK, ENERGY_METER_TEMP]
BO_ 1280 ACU_OK: 1 ECU
 SG_ bms_ok : 0|1@1+ (1,0) [0|1] "" Vector__XXX
 SG_ imd_ok : 1|1@1+ (1,0) [0|1] "" Vector__XXX
 SG_ latch_ok : 2|1@1+ (1,0) [0|1] "" Vector__XXX

BO_ 519 CAR_STATES: 3 ECU
 SG_ vehicle_state : 0|8@1+ (1,0) [0|255] "" Vector__XXX
 SG_ drivetrain_state : 8|8@1+ (1,0) [0|255] "" Vector__XXX
 SG_ drivebrain_in_control : 16|1@1+ (1,0) [0|1] "" Vector__XXX

BO_ 1220 FL_IR_TEMP_CH1_CH4: 8 ECU
 SG_ ir_temp_channel_1 : 7|16@0+ (0.1,-100) [-100.0|6453.5] "deg C" Vector__XXX
 SG_ ir_temp_channel_2 : 23|16@0+ (0.1,-100) [-100.0|6453.5] "deg C" Vector__XXX
 SG_ ir_temp_channel_3 : 39|16@0+ (0.1,-100) [-100.0|6453.5] "deg C" Vector__XXX
 SG_ ir_temp_channel_4 : 55|16@0+ (0.1,-100) [-100.0|6453.5] "deg C" Vector__XXX

BO_ 1221 FL_IR_TEMP_CH5_CH8: 8 ECU
 SG_ ir_temp_channel_5 : 7|16@0+ (0.1,-100) [-100.0|6453.5] "deg C" Vector__XXX
 SG_ ir_temp_channel_6 : 23|16@0+ (0.1,-100) [-100.0|6453.5] "deg C" Vector__XXX
 SG_ ir_temp_channel_7 : 39|16@0+ (0.1,-100) [-100.0|6453.5] "deg C" Vector__XXX
 SG_ ir_temp_channel_8 : 55|16@0+ (0.1,-100) [-100.0|6453.5] "deg C" Vector__XXX

BO_ 1222 FL_IR_TEMP_CH9_CH12: 8 ECU
 SG_ ir_temp_channel_9 : 7|16@0+ (0.1,-100) [-100.0|6453.5] "deg C" Vector__XXX
 SG_ ir_temp_channel_10 : 23|16@0+ (0.1,-100) [-100.0|6453.5] "deg C" Vector__XXX
 SG_ ir_temp_channel_11 : 39|16@0+ (0.1,-100) [-100.0|6453.5] "deg C" Vector__XXX
 SG_ ir_temp_channel_12 : 55|16@0+ (0.1,-100) [-100.0|6453.5] "deg C" Vector__XXX

BO_ 1223 FL_IR_TEMP_CH13_CH16: 8 ECU
 SG_ ir_temp_channel_13 : 7|16@0+ (0.1,-100) [-100.0|6453.5] "deg C" Vector__XXX
 SG_ ir_temp_channel_14 : 23|16@0+ (0.1,-100) [-100.0|6453.5] "deg C" Vector__XXX
 SG_ ir_temp_channel_15 : 39|16@0+ (0.1,-100) [-100.0|6453.5] "deg C" Vector__XXX
 SG_ ir_temp_channel_16 : 55|16@0+ (0.1,-100) [-100.0|6453.5] "deg C" Vector__XXX

BO_ 1224 FR_IR_TEMP_CH1_CH4: 8 ECU
 SG_ ir_temp_channel_1 : 7|16@0+ (0.1,-100) [-100.0|6453.5] "deg C" Vector__XXX
 SG_ ir_temp_channel_2 : 23|16@0+ (0.1,-100) [-100.0|6453.5] "deg C" Vector__XXX
 SG_ ir_temp_channel_3 : 39|16@0+ (0.1,-100) [-100.0|6453.5] "deg C" Vector__XXX
 SG_ ir_temp_channel_4 : 55|16@0+ (0.1,-100) [-100.0|6453.5] "deg C" Vector__XXX

BO_ 1225 FR_IR_TEMP_CH5_CH8: 8 ECU
 SG_ ir_temp_channel_5 : 7|16@0+ (0.1,-100) [-100.0|6453.5] "deg C" Vector__XXX
 SG_ ir_temp_channel_6 : 23|16@0+ (0.1,-100) [-100.0|6453.5] "deg C" Vector__XXX
 SG_ ir_temp_channel_7 : 39|16@0+ (0.1,-100) [-100.0|6453.5] "deg C" Vector__XXX
 SG_ ir_temp_channel_8 : 55|16@0+ (0.1,-100) [-100.0|6453.5] "deg C" Vector__XXX

BO_ 1226 FR_IR_TEMP_CH9_CH12: 8 ECU
 SG_ ir_temp_channel_9 : 7|16@0+ (0.1,-100) [-100.0|6453.5] "deg C" Vector__XXX
 SG_ ir_temp_channel_10 : 23|16@0+ (0.1,-100) [-100.0|6453.5] "deg C" Vector__XXX
 SG_ ir_temp_channel_11 : 39|16@0+ (0.1,-100) [-100.0|6453.5] "deg C" Vector__XXX
 SG_ ir_temp_channel_12 : 55|16@0+ (0.1,-100) [-100.0|6453.5] "deg C" Vector__XXX

BO_ 1227 FR_IR_TEMP_CH13_CH16: 8 ECU
 SG_ ir_temp_channel_13 : 7|16@0+ (0.1,-100) [-100.0|6453.5] "deg C" Vector__XXX
 SG_ ir_temp_channel_14 : 23|16@0+ (0.1,-100) [-100.0|6453.5] "deg C" Vector__XXX
 SG_ ir_temp_channel_15 : 39|16@0+ (0.1,-100) [-100.0|6453.5] "deg C" Vector__XXX
 SG_ ir_temp_channel_16 : 55|16@0+ (0.1,-100) [-100.0|6453.5] "deg C" Vector__XXX

BO_ 1228 RL_IR_TEMP_CH1_CH4: 8 ECU
 SG_ ir_temp_channel_1 : 7|16@0+ (0.1,-100) [-100.0|6453.5] "deg C" Vector__XXX
 SG_ ir_temp_channel_2 : 23|16@0+ (0.1,-100) [-100.0|6453.5] "deg C" Vector__XXX
 SG_ ir_temp_channel_3 : 39|16@0+ (0.1,-100) [-100.0|6453.5] "deg C" Vector__XXX
 SG_ ir_temp_channel_4 : 55|16@0+ (0.1,-100) [-100.0|6453.5] "deg C" Vector__XXX

BO_ 1229 RL_IR_TEMP_CH5_CH8: 8 ECU
 SG_ ir_temp_channel_5 : 7|16@0+ (0.1,-100) [-100.0|6453.5] "deg C" Vector__XXX
 SG_ ir_temp_channel_6 : 23|16@0+ (0.1,-100) [-100.0|6453.5] "deg C" Vector__XXX
 SG_ ir_temp_channel_7 : 39|16@0+ (0.1,-100) [-100.0|6453.5] "deg C" Vector__XXX
 SG_ ir_temp_channel_8 : 55|16@0+ (0.1,-100) [-100.0|6453.5] "deg C" Vector__XXX

BO_ 1230 RL_IR_TEMP_CH9_CH12: 8 ECU
 SG_ ir_temp_channel_9 : 7|16@0+ (0.1,-100) [-100.0|6453.5] "deg C" Vector__XXX
 SG_ ir_temp_channel_10 : 23|16@0+ (0.1,-100) [-100.0|6453.5] "deg C" Vector__XXX
 SG_ ir_temp_channel_11 : 39|16@0+ (0.1,-100) [-100.0|6453.5] "deg C" Vector__XXX
 SG_ ir_temp_channel_12 : 55|16@0+ (0.1,-100) [-100.0|6453.5] "deg C" Vector__XXX

BO_ 1231 RL_IR_TEMP_CH13_CH16: 8 ECU
 SG_ ir_temp_channel_13 : 7|16@0+ (0.1,-100) [-100.0|6453.5] "deg C" Vector__XXX
 SG_ ir_temp_channel_14 : 23|16@0+ (0.1,-100) [-100.0|6453.5] "deg C" Vector__XXX
 SG_ ir_temp_channel_15 : 39|16@0+ (0.1,-100) [-100.0|6453.5] "deg C" Vector__XXX
 SG_ ir_temp_channel_16 : 55|16@0+ (0.1,-100) [-100.0|6453.5] "deg C" Vector__XXX

BO_ 1232 RR_IR_TEMP_CH1_CH4: 8 ECU
 SG_ ir_temp_channel_1 : 7|16@0+ (0.1,-100) [-100.0|6453.5] "deg C" Vector__XXX
 SG_ ir_temp_channel_2 : 23|16@0+ (0.1,-100) [-100.0|6453.5] "deg C" Vector__XXX
 SG_ ir_temp_channel_3 : 39|16@0+ (0.1,-100) [-100.0|6453.5] "deg C" Vector__XXX
 SG_ ir_temp_channel_4 : 55|16@0+ (0.1,-100) [-100.0|6453.5] "deg C" Vector__XXX

BO_ 1233 RR_IR_TEMP_CH5_CH8: 8 ECU
 SG_ ir_temp_channel_5 : 7|16@0+ (0.1,-100) [-100.0|6453.5] "deg C" Vector__XXX
 SG_ ir_temp_channel_6 : 23|16@0+ (0.1,-100) [-100.0|6453.5] "deg C" Vector__XXX
 SG_ ir_temp_channel_7 : 39|16@0+ (0.1,-100) [-100.0|6453.5] "deg C" Vector__XXX
 SG_ ir_temp_channel_8 : 55|16@0+ (0.1,-100) [-100.0|6453.5] "deg C" Vector__XXX

BO_ 1234 RR_IR_TEMP_CH9_CH12: 8 ECU
 SG_ ir_temp_channel_9 : 7|16@0+ (0.1,-100) [-100.0|6453.5] "deg C" Vector__XXX
 SG_ ir_temp_channel_10 : 23|16@0+ (0.1,-100) [-100.0|6453.5] "deg C" Vector__XXX
 SG_ ir_temp_channel_11 : 39|16@0+ (0.1,-100) [-100.0|6453.5] "deg C" Vector__XXX
 SG_ ir_temp_channel_12 : 55|16@0+ (0.1,-100) [-100.0|6453.5] "deg C" Vector__XXX

BO_ 1235 RR_IR_TEMP_CH13_CH16: 8 ECU
 SG_ ir_temp_channel_13 : 7|16@0+ (0.1,-100) [-100.0|6453.5] "deg C" Vector__XXX
 SG_ ir_temp_channel_14 : 23|16@0+ (0.1,-100) [-100.0|6453.5] "deg C" Vector__XXX
 SG_ ir_temp_channel_15 : 39|16@0+ (0.1,-100) [-100.0|6453.5] "deg C" Vector__XXX
 SG_ ir_temp_channel_16 : 55|16@0+ (0.1,-100) [-100.0|6453.5] "deg C" Vector__XXX

BO_ 1236 RR_IR_TEMP_SENSOR_TEMP: 8 ECU
 SG_ ir_temp_sensor_temp : 7|16@0+ (0.1,-100) [-100.0|6453.5] "deg C" Vector__XXX

BO_ 1008 AERO_PRESSURE_SENSOR_11: 8 ECU
 SG_ aero_channel_0 : 7|16@0+ (0.14285714285,-53000) [-53000.0|-43637.85714332525] "uBar" Vector__XXX
 SG_ aero_channel_1 : 23|16@0+ (0.14285714285,-53000) [-53000.0|-43637.85714332525] "uBar" Vector__XXX
 SG_ aero_channel_2 : 39|16@0+ (0.14285714285,-53000) [-53000.0|-43637.85714332525] "uBar" Vector__XXX
 SG_ aero_channel_3 : 55|16@0+ (0.14285714285,-53000) [-53000.0|-43637.85714332525] "uBar" Vector__XXX

BO_ 1584 AERO_PRESSURE_SENSOR_31: 8 ECU
 SG_ aero_channel_0 : 7|16@0+ (0.14285714285,-53000) [-53000.0|-43637.85714332525] "uBar" Vector__XXX
 SG_ aero_channel_1 : 23|16@0+ (0.14285714285,-53000) [-53000.0|-43637.85714332525] "uBar" Vector__XXX
 SG_ aero_channel_2 : 39|16@0+ (0.14285714285,-53000) [-53000.0|-43637.85714332525] "uBar" Vector__XXX
 SG_ aero_channel_3 : 55|16@0+ (0.14285714285,-53000) [-53000.0|-43637.85714332525] "uBar" Vector__XXX

BO_ 1600 AERO_PRESSURE_SENSOR_41: 8 ECU
 SG_ aero_channel_0 : 7|16@0+ (0.14285714285,-53000) [-53000.0|-43637.85714332525] "uBar" Vector__XXX
 SG_ aero_channel_1 : 23|16@0+ (0.14285714285,-53000) [-53000.0|-43637.85714332525] "uBar" Vector__XXX
 SG_ aero_channel_2 : 39|16@0+ (0.14285714285,-53000) [-53000.0|-43637.85714332525] "uBar" Vector__XXX
 SG_ aero_channel_3 : 55|16@0+ (0.14285714285,-53000) [-53000.0|-43637.85714332525] "uBar" Vector__XXX

BO_ 1568 AERO_PRESSURE_SENSOR_21: 8 ECU
 SG_ aero_channel_0 : 7|16@0+ (0.14285714285,-53000) [-53000.0|-43637.85714332525] "uBar" Vector__XXX
 SG_ aero_channel_1 : 23|16@0+ (0.14285714285,-53000) [-53000.0|-43637.85714332525] "uBar" Vector__XXX
 SG_ aero_channel_2 : 39|16@0+ (0.14285714285,-53000) [-53000.0|-43637.85714332525] "uBar" Vector__XXX
 SG_ aero_channel_3 : 55|16@0+ (0.14285714285,-53000) [-53000.0|-43637.85714332525] "uBar" Vector__XXX

BO_ 1012 AERO_PRESSURE_SENSOR_12: 8 ECU
 SG_ aero_channel_4 : 7|16@0+ (0.14285714285,-53000) [-53000.0|-43637.85714332525] "uBar" Vector__XXX
 SG_ aero_channel_5 : 23|16@0+ (0.14285714285,-53000) [-53000.0|-43637.85714332525] "uBar" Vector__XXX
 SG_ aero_channel_6 : 39|16@0+ (0.14285714285,-53000) [-53000.0|-43637.85714332525] "uBar" Vector__XXX
 SG_ aero_channel_7 : 55|16@0+ (0.14285714285,-53000) [-53000.0|-43637.85714332525] "uBar" Vector__XXX

BO_ 800 AERO_PRESSURE_SENSOR_22: 8 ECU
 SG_ aero_channel_4 : 7|16@0+ (0.14285714285,-53000) [-53000.0|-43637.85714332525] "uBar" Vector__XXX
 SG_ aero_channel_5 : 23|16@0+ (0.14285714285,-53000) [-53000.0|-43637.85714332525] "uBar" Vector__XXX
 SG_ aero_channel_6 : 39|16@0+ (0.14285714285,-53000) [-53000.0|-43637.85714332525] "uBar" Vector__XXX
 SG_ aero_channel_7 : 55|16@0+ (0.14285714285,-53000) [-53000.0|-43637.85714332525] "uBar" Vector__XXX

BO_ 816 AERO_PRESSURE_SENSOR_32: 8 ECU
 SG_ aero_channel_4 : 7|16@0+ (0.14285714285,-53000) [-53000.0|-43637.85714332525] "uBar" Vector__XXX
 SG_ aero_channel_5 : 23|16@0+ (0.14285714285,-53000) [-53000.0|-43637.85714332525] "uBar" Vector__XXX
 SG_ aero_channel_6 : 39|16@0+ (0.14285714285,-53000) [-53000.0|-43637.85714332525] "uBar" Vector__XXX
 SG_ aero_channel_7 : 55|16@0+ (0.14285714285,-53000) [-53000.0|-43637.85714332525] "uBar" Vector__XXX

BO_ 832 AERO_PRESSURE_SENSOR_42: 8 ECU
 SG_ aero_channel_4 : 7|16@0+ (0.14285714285,-53000) [-53000.0|-43637.85714332525] "uBar" Vector__XXX
 SG_ aero_channel_5 : 23|16@0+ (0.14285714285,-53000) [-53000.0|-43637.85714332525] "uBar" Vector__XXX
 SG_ aero_channel_6 : 39|16@0+ (0.14285714285,-53000) [-53000.0|-43637.85714332525] "uBar" Vector__XXX
 SG_ aero_channel_7 : 55|16@0+ (0.14285714285,-53000) [-53000.0|-43637.85714332525] "uBar" Vector__XXX

BO_ 330 INV1_OVERLOAD: 8 ECU
 SG_ inverter_overload_percentage : 0|16@1+ (0.1,0) [0.0|6553.5] "" Vector__XXX
 SG_ motor_overload_percentage : 16|16@1+ (0.1,0) [0.0|6553.5] "" Vector__XXX

BO_ 340 INV2_OVERLOAD: 4 ECU
 SG_ inverter_overload_percentage : 0|16@1+ (0.1,0) [0.0|6553.5] "" Vector__XXX
 SG_ motor_overload_percentage : 16|16@1+ (0.1,0) [0.0|6553.5] "" Vector__XXX

BO_ 310 INV3_OVERLOAD: 4 ECU
 SG_ inverter_overload_percentage : 0|16@1+ (0.1,0) [0.0|6553.5] "" Vector__XXX
 SG_ motor_overload_percentage : 16|16@1+ (0.1,0) [0.0|6553.5] "" Vector__XXX

BO_ 320 INV4_OVERLOAD: 4 ECU
 SG_ inverter_overload_percentage : 0|16@1+ (0.1,0) [0.0|6553.5] "" Vector__XXX
 SG_ motor_overload_percentage : 16|16@1+ (0.1,0) [0.0|6553.5] "" Vector__XXX

BO_ 269 ENERGY_METER_MEAS: 8 ECU
 SG_ current_A : 7|32@0- (1,0) [-2147483648|2147483647] "" Vector__XXX
 SG_ voltage_V : 39|32@0- (1,0) [-2147483648|2147483647] "" Vector__XXX

BO_ 1037 ENERGY_METER_STATUS: 8 ECU
 SG_ em_violation : 0|1@1+ (1,0) [0|1] "" Vector__XXX
 SG_ em_logging : 1|1@1+ (1,0) [0|1] "" Vector__XXX
 SG_ em_energy_w_hr : 15|32@0- (1,0) [-2147483648|2147483647] "" Vector__XXX

BO_ 1550 ENERGY_METER_TEMP: 8 ECU
 SG_ em_temp_sig_index : 7|3@0+ (1,0) [0|1.0] "" Vector__XXX
 SG_ em_num_sensors : 4|5@0+ (1,0) [0|31] "" Vector__XXX
 SG_ em_min_temp : 15|8@0+ (0.5,0) [0.0|127.5] "" Vector__XXX
 SG_ em_max_temp : 23|8@0+ (0.5,0) [0.0|127.5] "" Vector__XXX
 SG_ em_temp_0 : 31|8@0+ (0.5,0) [0.0|127.5] "" Vector__XXX
 SG_ em_temp_1 : 39|8@0+ (0.5,0) [0.0|127.5] "" Vector__XXX
 SG_ em_temp_2 : 47|8@0+ (0.5,0) [0.0|127.5] "" Vector__XXX
 SG_ em_temp_3 : 55|8@0+ (0.5,0) [0.0|127.5] "" Vector__XXX
 SG_ em_temp_4 : 63|8@0+ (0.5,0) [0.0|127.5] "" Vector__XXX

BO_ 1281 DRIVEBRAIN_LATENCY_TIMES: 8 ECU
 SG_ telem_latency_millis : 0|32@1+ (1,0) [0|4294967295] "" Vector__XXX
 SG_ aux_latency_millis : 32|32@1+ (1,0) [0|4294967295] "" Vector__XXX

BO_ 1282 DRIVEBRAIN_LATENCY_STATUSES: 8 ECU
 SG_ db_telem_timing_fault : 0|1@1+ (1,0) [0|1] "" Vector__XXX
 SG_ db_aux_timing_fault : 1|1@1+ (1,0) [0|1] "" Vector__XXX

BO_ 1283 FLOWMETER_DATA: 8 ECU
 SG_ flow_rate : 0|32@1- (1,0) [-2147483648|2147483647] "" Vector__XXX

BO_ 1639 BRAKE_PRESSURE: 8 ECU
 SG_ brake_pressure_1 : 0|16@1+ (1,0) [0|65535] "" Vector__XXX
 SG_ brake_pressure_2 : 16|16@1+ (1,0) [0|65535] "" Vector__XXX

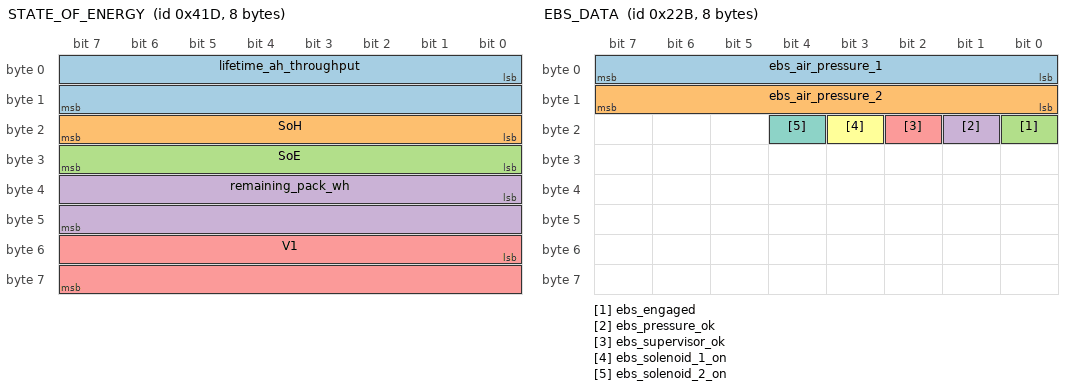
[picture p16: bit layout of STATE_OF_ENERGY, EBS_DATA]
BO_ 1053 STATE_OF_ENERGY: 8 ECU
 SG_ lifetime_ah_throughput : 0|16@1+ (0.02,0) [0.0|1310.7] "Ah" Vector__XXX
 SG_ SoH : 16|8@1+ (0.5,0) [0.0|127.5] "percent" Vector__XXX
 SG_ SoE : 24|8@1+ (0.5,0) [0.0|127.5] "percent" Vector__XXX
 SG_ remaining_pack_wh : 32|16@1+ (0.1,0) [0.0|6553.5] "Wh" Vector__XXX
 SG_ V1 : 48|16@1+ (0.0001,0) [0.0|6.5535000000000005] "" Vector__XXX

BO_ 555 EBS_DATA: 8 ECU
 SG_ ebs_air_pressure_1 : 0|8@1+ (1,0) [0|255] "psi" Vector__XXX
 SG_ ebs_air_pressure_2 : 8|8@1+ (1,0) [0|255] "psi" Vector__XXX
 SG_ ebs_engaged : 16|1@1+ (1,0) [0|1] "" Vector__XXX
 SG_ ebs_pressure_ok : 17|1@1+ (1,0) [0|1] "" Vector__XXX
 SG_ ebs_supervisor_ok : 18|1@1+ (1,0) [0|1] "" Vector__XXX
 SG_ ebs_solenoid_1_on : 19|1@1+ (1,0) [0|1] "" Vector__XXX
 SG_ ebs_solenoid_2_on : 20|1@1+ (1,0) [0|1] "" Vector__XXX

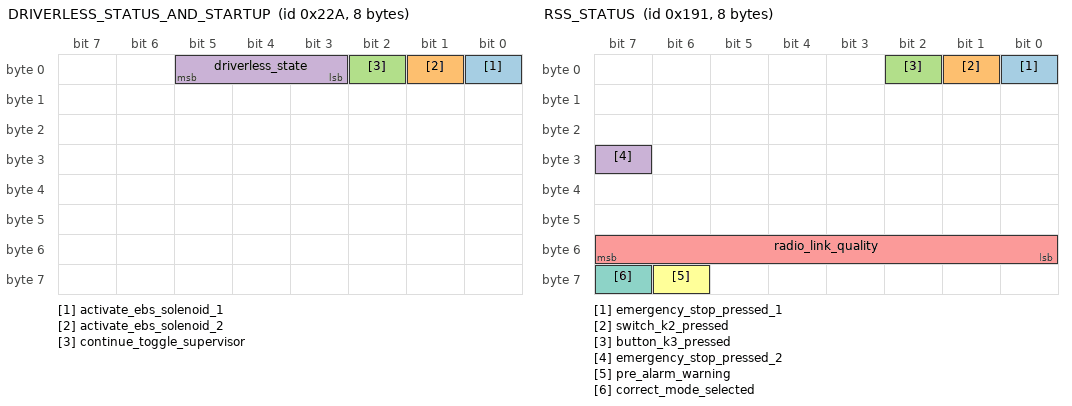
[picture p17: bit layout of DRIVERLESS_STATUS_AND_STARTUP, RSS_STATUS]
BO_ 554 DRIVERLESS_STATUS_AND_STARTUP: 8 ECU
 SG_ activate_ebs_solenoid_1 : 0|1@1+ (1,0) [0|1] "" Vector__XXX
 SG_ activate_ebs_solenoid_2 : 1|1@1+ (1,0) [0|1] "" Vector__XXX
 SG_ continue_toggle_supervisor : 2|1@1+ (1,0) [0|1] "" Vector__XXX
 SG_ driverless_state : 3|3@1+ (1,0) [0|7] "" Vector__XXX

BO_ 556 FDC_DRIVERLESS_MISSION: 8 ECU
 SG_ driverless_mission : 0|3@1+ (1,0) [0|7] "" Vector__XXX

BO_ 1809 RSS_BOOT_UP: 1 ECU
 SG_ rss_initialization : 0|8@1+ (1,0) [0|255] "" Vector__XXX

BO_ 0 SET_OPERATING_MODE: 2 ECU
 SG_ requested_state : 0|8@1+ (1,0) [0|255] "" Vector__XXX
 SG_ target_node : 8|8@1+ (1,0) [0|255] "" Vector__XXX

BO_ 401 RSS_STATUS: 8 ECU
 SG_ emergency_stop_pressed_1 : 0|1@1+ (1,0) [0|1] "" Vector__XXX
 SG_ switch_k2_pressed : 1|1@1+ (1,0) [0|1] "" Vector__XXX
 SG_ button_k3_pressed : 2|1@1+ (1,0) [0|1] "" Vector__XXX
 SG_ emergency_stop_pressed_2 : 31|1@1+ (1,0) [0|1] "" Vector__XXX
 SG_ radio_link_quality : 48|8@1+ (1,0) [0|255] "%" Vector__XXX
 SG_ pre_alarm_warning : 62|1@1+ (1,0) [0|1] "" Vector__XXX
 SG_ correct_mode_selected : 63|1@1+ (1,0) [0|1] "" Vector__XXX

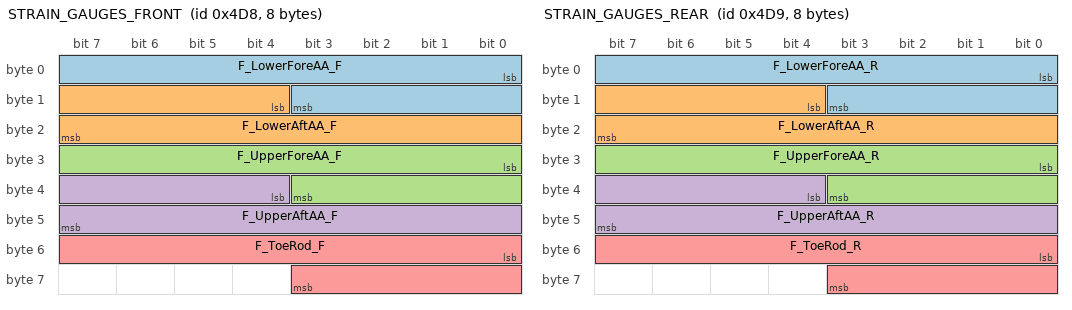
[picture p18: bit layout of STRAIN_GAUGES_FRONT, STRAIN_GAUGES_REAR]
BO_ 1240 STRAIN_GAUGES_FRONT: 8 ECU
 SG_ F_LowerForeAA_F : 0|12@1+ (1,0) [0|4095] "Newtons" Vector__XXX
 SG_ F_LowerAftAA_F : 12|12@1+ (1,0) [0|4095] "Newtons" Vector__XXX
 SG_ F_UpperForeAA_F : 24|12@1+ (1,0) [0|4095] "Newtons" Vector__XXX
 SG_ F_UpperAftAA_F : 36|12@1+ (1,0) [0|4095] "Newtons" Vector__XXX
 SG_ F_ToeRod_F : 48|12@1+ (1,0) [0|4095] "Newtons" Vector__XXX

BO_ 1241 STRAIN_GAUGES_REAR: 8 ECU
 SG_ F_LowerForeAA_R : 0|12@1+ (1,0) [0|4095] "Newtons" Vector__XXX
 SG_ F_LowerAftAA_R : 12|12@1+ (1,0) [0|4095] "Newtons" Vector__XXX
 SG_ F_UpperForeAA_R : 24|12@1+ (1,0) [0|4095] "Newtons" Vector__XXX
 SG_ F_UpperAftAA_R : 36|12@1+ (1,0) [0|4095] "Newtons" Vector__XXX
 SG_ F_ToeRod_R : 48|12@1+ (1,0) [0|4095] "Newtons" Vector__XXX

BO_ 1538 PitchAndRoll: 4 SensoricSolutionsOMSRace
 SG_ Roll : 0|16@1- (0.003,0) [-90|90] "°"  SensoricSolutionsOMSRace
 SG_ Pitch : 16|16@1- (0.003,0) [-90|90] "°"  SensoricSolutionsOMSRace

BO_ 1539 AccHor: 6 SensoricSolutionsOMSRace
 SG_ AccXHor : 0|16@1- (0.02,0) [-200.0|200.0] "m/s^2"  SensoricSolutionsOMSRace
 SG_ AccYHor : 16|16@1- (0.02,0) [-200.0|200.0] "m/s^2"  SensoricSolutionsOMSRace
 SG_ AccZHor : 32|16@1- (0.02,0) [-200.0|200.0] "m/s^2"  SensoricSolutionsOMSRace

BO_ 1540 RateHor: 6 SensoricSolutionsOMSRace
 SG_ RateXHor : 0|16@1- (0.02,0) [-500.0|500.0] "°/s"  SensoricSolutionsOMSRace
 SG_ RateYHor : 16|16@1- (0.02,0) [-500.0|500.0] "°/s"  SensoricSolutionsOMSRace
 SG_ RateZHor : 32|16@1- (0.02,0) [-500.0|500.0] "°/s"  SensoricSolutionsOMSRace

BO_ 1541 VelAndAng: 8 SensoricSolutionsOMSRace
 SG_ VelX : 0|16@1- (0.02,0) [-450|450] "km/h"  SensoricSolutionsOMSRace
 SG_ VelY : 16|16@1- (0.02,0) [-100|100] "km/h"  SensoricSolutionsOMSRace
 SG_ VelA : 32|16@1- (0.02,0) [0|450] "km/h"  SensoricSolutionsOMSRace
 SG_ AngS : 48|16@1- (0.003,0) [-40|40] "°"  SensoricSolutionsOMSRace

BO_ 1545 VelAndAngSp: 8 SensoricSolutionsOMSRace
 SG_ VelASp : 0|16@1- (0.02,0) [0|450] "km/h"  SensoricSolutionsOMSRace
 SG_ AngSSp : 16|16@1- (0.003,0) [-40|40] "°"  SensoricSolutionsOMSRace
 SG_ QualityCh0 : 32|16@1+ (1,0) [0|65535] ""  SensoricSolutionsOMSRace
 SG_ QualityCh1 : 48|16@1+ (1,0) [0|65535] ""  SensoricSolutionsOMSRace

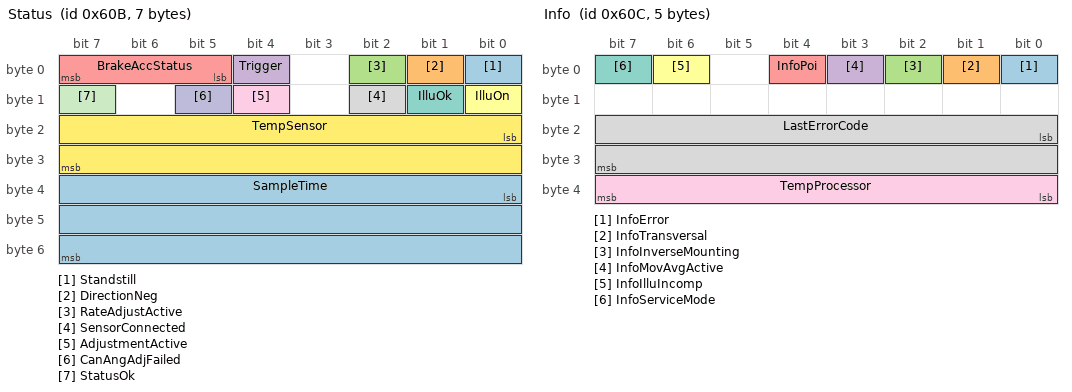
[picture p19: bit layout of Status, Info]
BO_ 1547 Status: 7 SensoricSolutionsOMSRace
 SG_ Standstill : 0|1@1+ (1,0) [0|1] ""  SensoricSolutionsOMSRace
 SG_ DirectionNeg : 1|1@1+ (1,0) [0|1] ""  SensoricSolutionsOMSRace
 SG_ RateAdjustActive : 2|1@1+ (1,0) [0|1] ""  SensoricSolutionsOMSRace
 SG_ Trigger : 4|1@1+ (1,0) [0|1] ""  SensoricSolutionsOMSRace
 SG_ BrakeAccStatus : 5|3@1+ (1,0) [0|5] ""  SensoricSolutionsOMS7
 SG_ IlluOn : 8|1@1+ (1,0) [0|1] ""  SensoricSolutionsOMSRace
 SG_ IlluOk : 9|1@1+ (1,0) [0|1] ""  SensoricSolutionsOMSRace
 SG_ SensorConnected : 10|1@1+ (1,0) [0|1] ""  SensoricSolutionsOMSRace
 SG_ AdjustmentActive : 12|1@1+ (1,0) [0|1] ""  SensoricSolutionsOMSRace
 SG_ CanAngAdjFailed : 13|1@1+ (1,0) [0|1] ""  SensoricSolutionsOMSRace
 SG_ StatusOk : 15|1@1+ (1,0) [0|1] ""  SensoricSolutionsOMSRace
 SG_ TempSensor : 16|16@1- (0.1,0) [-20|85] "°C"  SensoricSolutionsOMSRace
 SG_ SampleTime : 32|24@1+ (0.001,0) [0|16777.215] "s"  SensoricSolutionsOMSRace

BO_ 1548 Info: 5 SensoricSolutionsOMSRace
 SG_ InfoError : 0|1@1+ (1,0) [0|1] ""  SensoricSolutionsOMSRace
 SG_ InfoTransversal : 1|1@1+ (1,0) [0|1] ""  SensoricSolutionsOMSRace
 SG_ InfoInverseMounting : 2|1@1+ (1,0) [0|1] ""  SensoricSolutionsOMSRace
 SG_ InfoMovAvgActive : 3|1@1+ (1,0) [0|1] ""  SensoricSolutionsOMSRace
 SG_ InfoPoi : 4|1@1+ (1,0) [0|1] ""  SensoricSolutionsOMSRace
 SG_ InfoIlluIncomp : 6|1@1+ (1,0) [0|1] ""  SensoricSolutionsOMSRace
 SG_ InfoServiceMode : 7|1@1+ (1,0) [0|1] ""  SensoricSolutionsOMSRace
 SG_ LastErrorCode : 16|16@1+ (1,0) [0|65535] ""  SensoricSolutionsOMSRace
 SG_ TempProcessor : 32|8@1- (1,0) [-128|127] "°C"  SensoricSolutionsOMSRace

BO_ 1549 StaticInfo: 8 SensoricSolutionsOMSRace
 SG_ SerialEcu : 0|16@1+ (1,0) [0|65535] ""  SensoricSolutionsOMSRace
 SG_ SerialSensor : 16|16@1+ (1,0) [0|65535] ""  SensoricSolutionsOMSRace
 SG_ FwVersion : 32|24@1+ (1,0) [0|16777215] ""  SensoricSolutionsOMSRace
 SG_ ParamSetLoaded : 56|8@1+ (1,0) [0|255] ""  SensoricSolutionsOMSRace

CM_ SG_ 2550588916 max_charging_current_low "Unused for any PCAN stuff only for Elcon Charger";
CM_ SG_ 2550588916 max_charging_current_high "Unused for any PCAN stuff only for Elcon Charger";
CM_ SG_ 2550588916 max_charging_voltage_low "Unused for any PCAN stuff only for Elcon Charger";
CM_ SG_ 2550588916 max_charging_voltage_high "Unused for any PCAN stuff only for Elcon Charger";
CM_ SG_ 2033 in_steering_calibration_state "Input from VCR to tell VCF if steering can calibrate or not";
CM_ SG_ 768 dim_button "Dim button on dash";
CM_ SG_ 768 dash_dial_mode "Dashboard dial position";
CM_ BO_ 256 "Contains the voltage and current readings from the Energy Meter. Sent by the AMS.";
CM_ SG_ 256 em_voltage "The voltage, in Volts, measured by the Energy Meter.";
CM_ SG_ 256 em_current "The current draw, in amps, measured by the Energy Meter.";
CM_ BO_ 1024 "Forwarded directly from the Energy Meter with no modifications. See datasheet for more specifications.";
CM_ SG_ 1024 logging "Whether or not the energy meter is currently logging data.";
CM_ SG_ 1024 overpower_error "Whether or not the Energy Meter is reading an over-power error.";
CM_ SG_ 1024 overvoltage_error "Whether or not the energy meter is reading an over-voltage error.";
CM_ SG_ 1024 current_gain "This selects the \"gain\" mode for the EM current measurements. The specific multipliers for each gain mode are configured with the EMD Tool.";
CM_ SG_ 1024 voltage_gain "This selects the \"gain\" mode for the EM voltage measurements. The specific multipliers for each gain mode are configured with the EMD Tool.";
CM_ SG_ 245 thermistor_motor_fr "Motor cooling loop temperature";
CM_ SG_ 245 thermistor_motor_fl "Motor cooling loop temperature";
CM_ SG_ 153 negative_torque_limit "AMK made up unit";
CM_ SG_ 153 positive_torque_limit "Made up units from AMK";
CM_ SG_ 258 negative_torque_limit "AMK made up unit";
CM_ SG_ 258 positive_torque_limit "Made up units from AMK";
CM_ SG_ 151 negative_torque_limit "AMK made up unit";
CM_ SG_ 151 positive_torque_limit "Made up units from AMK";
CM_ SG_ 152 negative_torque_limit "AMK made up unit";
CM_ SG_ 152 positive_torque_limit "Made up units from AMK";
CM_ SG_ 1072 RL_TTPMS_SN "Serial Number";
CM_ SG_ 192 brake_pedal "the scaled brake pedal value between 0 and 1";
CM_ SG_ 192 accel_pedal "the scaled accelerator pedal value";
CM_ SG_ 192 implaus_exceeded_max_duration "a pedal implausibility has been present for longer than allowed";
CM_ SG_ 192 brake_accel_implausibility "brake and accel are pressed";
CM_ SG_ 1054 charge_coulombs "The charge in the accumulator, in Coulombs";
CM_ SG_ 1054 min_cell_voltage_est "Lowest-cell-voltage estimate based on the state of charge, according to VOLTAGE_LOOKUP_TABLE. Ex: 87% SoC would display 3.798V.";
CM_ SG_ 1054 SoC "The charge in the accumulator, as a percentage.";
CM_ BO_ 1055 "Steering reading; system and sensor status";
CM_ SG_ 1055 steering_output_steering_angle "converted angle for best sensor";
CM_ SG_ 1055 steering_digital_raw "raw measurement by digital steering encoder";
CM_ SG_ 1055 steering_analog_raw "raw measurement as measured by bottom steering analog sensor";
CM_ SG_ 1220 ir_temp_channel_4 "IR temp sensor channel reading in degrees C";
CM_ SG_ 1220 ir_temp_channel_3 "IR temp sensor channel reading in degrees C";
CM_ SG_ 1220 ir_temp_channel_2 "IR temp sensor channel reading in degrees C";
CM_ SG_ 1220 ir_temp_channel_1 "IR temp sensor channel reading in degrees C";
CM_ SG_ 1221 ir_temp_channel_8 "IR temp sensor channel reading in degrees C";
CM_ SG_ 1221 ir_temp_channel_7 "IR temp sensor channel reading in degrees C";
CM_ SG_ 1221 ir_temp_channel_6 "IR temp sensor channel reading in degrees C";
CM_ SG_ 1221 ir_temp_channel_5 "IR temp sensor channel reading in degrees C";
CM_ SG_ 1222 ir_temp_channel_12 "IR temp sensor channel reading in degrees C";
CM_ SG_ 1222 ir_temp_channel_11 "IR temp sensor channel reading in degrees C";
CM_ SG_ 1222 ir_temp_channel_10 "IR temp sensor channel reading in degrees C";
CM_ SG_ 1222 ir_temp_channel_9 "IR temp sensor channel reading in degrees C";
CM_ SG_ 1223 ir_temp_channel_16 "IR temp sensor channel reading in degrees C";
CM_ SG_ 1223 ir_temp_channel_15 "IR temp sensor channel reading in degrees C";
CM_ SG_ 1223 ir_temp_channel_14 "IR temp sensor channel reading in degrees C";
CM_ SG_ 1223 ir_temp_channel_13 "IR temp sensor channel reading in degrees C";
CM_ SG_ 1224 ir_temp_channel_4 "IR temp sensor channel reading in degrees C";
CM_ SG_ 1224 ir_temp_channel_3 "IR temp sensor channel reading in degrees C";
CM_ SG_ 1224 ir_temp_channel_2 "IR temp sensor channel reading in degrees C";
CM_ SG_ 1224 ir_temp_channel_1 "IR temp sensor channel reading in degrees C";
CM_ SG_ 1225 ir_temp_channel_8 "IR temp sensor channel reading in degrees C";
CM_ SG_ 1225 ir_temp_channel_7 "IR temp sensor channel reading in degrees C";
CM_ SG_ 1225 ir_temp_channel_6 "IR temp sensor channel reading in degrees C";
CM_ SG_ 1225 ir_temp_channel_5 "IR temp sensor channel reading in degrees C";
CM_ SG_ 1226 ir_temp_channel_12 "IR temp sensor channel reading in degrees C";
CM_ SG_ 1226 ir_temp_channel_11 "IR temp sensor channel reading in degrees C";
CM_ SG_ 1226 ir_temp_channel_10 "IR temp sensor channel reading in degrees C";
CM_ SG_ 1226 ir_temp_channel_9 "IR temp sensor channel reading in degrees C";
CM_ SG_ 1227 ir_temp_channel_16 "IR temp sensor channel reading in degrees C";
CM_ SG_ 1227 ir_temp_channel_15 "IR temp sensor channel reading in degrees C";
CM_ SG_ 1227 ir_temp_channel_14 "IR temp sensor channel reading in degrees C";
CM_ SG_ 1227 ir_temp_channel_13 "IR temp sensor channel reading in degrees C";
CM_ SG_ 1228 ir_temp_channel_4 "IR temp sensor channel reading in degrees C";
CM_ SG_ 1228 ir_temp_channel_3 "IR temp sensor channel reading in degrees C";
CM_ SG_ 1228 ir_temp_channel_2 "IR temp sensor channel reading in degrees C";
CM_ SG_ 1228 ir_temp_channel_1 "IR temp sensor channel reading in degrees C";
CM_ SG_ 1229 ir_temp_channel_8 "IR temp sensor channel reading in degrees C";
CM_ SG_ 1229 ir_temp_channel_7 "IR temp sensor channel reading in degrees C";
CM_ SG_ 1229 ir_temp_channel_6 "IR temp sensor channel reading in degrees C";
CM_ SG_ 1229 ir_temp_channel_5 "IR temp sensor channel reading in degrees C";
CM_ SG_ 1230 ir_temp_channel_12 "IR temp sensor channel reading in degrees C";
CM_ SG_ 1230 ir_temp_channel_11 "IR temp sensor channel reading in degrees C";
CM_ SG_ 1230 ir_temp_channel_10 "IR temp sensor channel reading in degrees C";
CM_ SG_ 1230 ir_temp_channel_9 "IR temp sensor channel reading in degrees C";
CM_ SG_ 1231 ir_temp_channel_16 "IR temp sensor channel reading in degrees C";
CM_ SG_ 1231 ir_temp_channel_15 "IR temp sensor channel reading in degrees C";
CM_ SG_ 1231 ir_temp_channel_14 "IR temp sensor channel reading in degrees C";
CM_ SG_ 1231 ir_temp_channel_13 "IR temp sensor channel reading in degrees C";
CM_ SG_ 1232 ir_temp_channel_4 "IR temp sensor channel reading in degrees C";
CM_ SG_ 1232 ir_temp_channel_3 "IR temp sensor channel reading in degrees C";
CM_ SG_ 1232 ir_temp_channel_2 "IR temp sensor channel reading in degrees C";
CM_ SG_ 1232 ir_temp_channel_1 "IR temp sensor channel reading in degrees C";
CM_ SG_ 1233 ir_temp_channel_8 "IR temp sensor channel reading in degrees C";
CM_ SG_ 1233 ir_temp_channel_7 "IR temp sensor channel reading in degrees C";
CM_ SG_ 1233 ir_temp_channel_6 "IR temp sensor channel reading in degrees C";
CM_ SG_ 1233 ir_temp_channel_5 "IR temp sensor channel reading in degrees C";
CM_ SG_ 1234 ir_temp_channel_12 "IR temp sensor channel reading in degrees C";
CM_ SG_ 1234 ir_temp_channel_11 "IR temp sensor channel reading in degrees C";
CM_ SG_ 1234 ir_temp_channel_10 "IR temp sensor channel reading in degrees C";
CM_ SG_ 1234 ir_temp_channel_9 "IR temp sensor channel reading in degrees C";
CM_ SG_ 1235 ir_temp_channel_16 "IR temp sensor channel reading in degrees C";
CM_ SG_ 1235 ir_temp_channel_15 "IR temp sensor channel reading in degrees C";
CM_ SG_ 1235 ir_temp_channel_14 "IR temp sensor channel reading in degrees C";
CM_ SG_ 1235 ir_temp_channel_13 "IR temp sensor channel reading in degrees C";
CM_ BO_ 1236 "Izze IRTS-V3 brake sensor (datasheet Rev.D) internal package temperature. Keep below 85 deg C";
CM_ SG_ 1236 ir_temp_sensor_temp "IR temp sensor internal package temperature in degrees C";
CM_ SG_ 330 motor_overload_percentage "the current overload of the motor according to the i2t calc";
CM_ SG_ 330 inverter_overload_percentage "the current overload of the inverter according to the i2t calc";
CM_ SG_ 340 motor_overload_percentage "the current overload of the motor according to the i2t calc";
CM_ SG_ 340 inverter_overload_percentage "the current overload of the inverter according to the i2t calc";
CM_ SG_ 310 motor_overload_percentage "the current overload of the motor according to the i2t calc";
CM_ SG_ 310 inverter_overload_percentage "the current overload of the inverter according to the i2t calc";
CM_ SG_ 320 motor_overload_percentage "the current overload of the motor according to the i2t calc";
CM_ SG_ 320 inverter_overload_percentage "the current overload of the inverter according to the i2t calc";
CM_ SG_ 555 ebs_engaged "brakes activated";
CM_ BO_ 1809 "Msg sent by RSS on boot up";
CM_ SG_ 1809 rss_initialization "Initialization byte sent by the RSS";
CM_ BO_ 0 "Msg sent to the RSS to set the operating mode";
CM_ SG_ 0 target_node "Target node to put in the requested state";
CM_ SG_ 0 requested_state "State request to the RSS";
CM_ BO_ 401 "Status of the RSS";
CM_ SG_ 401 correct_mode_selected "Correct mode selected";
CM_ SG_ 401 pre_alarm_warning "Pre-alarm warning triggered 200ms in advance of a shutdown";
CM_ SG_ 401 radio_link_quality "Radio link quality";
CM_ SG_ 401 emergency_stop_pressed_2 "Emergency stop button pressed (second location)";
CM_ SG_ 401 button_k3_pressed "Button K2 pressed";
CM_ SG_ 401 switch_k2_pressed "Switch K2 pressed";
CM_ SG_ 401 emergency_stop_pressed_1 "Emergency stop button pressed (first location)";
CM_ BO_ 1240 "Front strain gauge measurements";
CM_ SG_ 1240 F_ToeRod_F "Force on the front toe rod";
CM_ SG_ 1240 F_UpperAftAA_F "Force on the front upper aft A arm";
CM_ SG_ 1240 F_UpperForeAA_F "Force on the front upper fore A arm";
CM_ SG_ 1240 F_LowerAftAA_F "Force on the front lower aft A arm";
CM_ SG_ 1240 F_LowerForeAA_F "Force on the front lower fore A arm";
CM_ BO_ 1241 "Rear strain gauge measurements";
CM_ SG_ 1241 F_ToeRod_R "Force on the rear toe rod";
CM_ SG_ 1241 F_UpperAftAA_R "Force on the rear upper aft A arm";
CM_ SG_ 1241 F_UpperForeAA_R "Force on the rear upper fore A arm";
CM_ SG_ 1241 F_LowerAftAA_R "Force on the rear lower aft A arm";
CM_ SG_ 1241 F_LowerForeAA_R "Force on the rear lower fore A arm";
BA_DEF_ BO_  "GenMsgCycleTimeus" INT 100 60000000;
BA_DEF_DEF_  "GenMsgCycleTimeus" 1000;
BA_ "GenMsgCycleTimeus" BO_ 1548 1000000;
BA_ "GenMsgCycleTimeus" BO_ 1549 1000000;
VAL_ 519 drivetrain_state 0 "NOT_CONNECTED" 1 "NOT_ENABLED_NO_HV_PRESENT" 2 "NOT_ENABLED_HV_PRESENT" 3 "INVERTERS_READY" 4 "INVERTERS_HV_ENABLED" 5 "ENABLED_DRIVE_MODE" 6 "ERROR" 7 "CLEARING_ERRORS" ;
VAL_ 519 vehicle_state 0 "TRACTIVE_SYSTEM_NOT_ACTIVE" 1 "TRACTIVE_SYSTEM_ACTIVE" 2 "WANTING_READY_TO_DRIVE" 3 "READY_TO_DRIVE" 4 "WANTING_RECALIBRATE_PEDALS" 5 "RECALIBRATING_PEDALS" 6 "WANTING_RECALIBRATE_STEERING" 7 "RECALIBRATING_STEERING" ;
VAL_ 554 driverless_state 0 "OFF" 1 "STARTUP_NO_TS" 2 "STARTUP_TS_ACTIVE" 3 "READY" 4 "DRIVING" 5 "EMERGENCY" 6 "FINISHED" ;
VAL_ 556 driverless_mission 0 "INSPECTION" 1 "MANUAL_MODE" 2 "EBS_TEST" 3 "ACCEL" 4 "SKIDPAD" 5 "AUTOX" ;
SIG_VALTYPE_ 269 current_A : 1;
SIG_VALTYPE_ 269 voltage_V : 1;
SIG_VALTYPE_ 1037 em_energy_w_hr : 1;
SIG_VALTYPE_ 1283 flow_rate : 1;
